VERSION ""

NS_ :

BS_:

BU_: ESC

VAL_TABLE_ RollingCounter_0x132 15 "Invalid";
VAL_TABLE_ ESC_HSA_Control_Status 1 "active" 0 "inactive";
VAL_TABLE_ ESC_HSA_Status_Fault 1 " HSA Defective" 0 "HSA Normale";
VAL_TABLE_ ESC_TcsDisableSts 3 "signal invalid" 2 "reservred" 1 "disabled" 0 "enabled";
VAL_TABLE_ ESC_TcsCtrlActv 1 "active" 0 "inactive";
VAL_TABLE_ ESC_TcsFlgFlt 1 "failure" 0 "no failure";
VAL_TABLE_ ESC_EscDisableSts 1 "disabled" 0 "enabled";
VAL_TABLE_ ESC_EscCtrlActv 1 "active" 0 "inactive";
VAL_TABLE_ ESC_EscFlgFlt 1 "failure" 0 "no failure";
VAL_TABLE_ ESC_HBAFlgFlt 1 "failure" 0 "no failure";
VAL_TABLE_ ESC_HbaCtrlActv 1 "active" 0 "inactive";
VAL_TABLE_ ESC_SlopeGradeAngle 255 "Invalid";
VAL_TABLE_ ESC_MasterCylinderPressure 4095 "Invalid";
VAL_TABLE_ RollingCounter_0x142 15 "Invalid";
VAL_TABLE_ AbsDiagSessionLampReq_Reserved 1 "lamp on" 0 "lamp off";
VAL_TABLE_ ABS_AbsCtrlActv 1 "active" 0 "inactive";
VAL_TABLE_ ABS_EbdFlgFlt 1 "failure" 0 "no failure";
VAL_TABLE_ ABS_AbsFlgFlt 1 "failure" 0 "no failure";
VAL_TABLE_ ABS_ESS_Active 1 "active" 0 "inactive";
VAL_TABLE_ ABS_LowBrakeFluid 1 "failure" 0 "no failure";
VAL_TABLE_ RollingCounter_0x332 15 "Invalid";
VAL_TABLE_ ABS_LFWhlSpdRaw 32767 "Invalid";
VAL_TABLE_ ABS_LFWhlSpdRawValid 1 "Valid" 0 "Invalid";
VAL_TABLE_ ABS_RFWhlSpdRaw 32767 "Invalid";
VAL_TABLE_ ABS_RFWhlSpdRawValid 1 "Valid" 0 "Invalid";
VAL_TABLE_ RollingCounter_0x342 15 "Invalid";
VAL_TABLE_ ABS_LRWhlSpdRaw 32767 "Invalid";
VAL_TABLE_ ABS_LRWhlSpdRawValid 1 "Valid" 0 "Invalid";
VAL_TABLE_ ABS_RRWhlSpdRaw 32767 "Invalid";
VAL_TABLE_ ABS_RRWhlSpdRawValid 1 "Valid" 0 "Invalid";
VAL_TABLE_ ABS_VehSpd 32767 "Invalid";
VAL_TABLE_ ABS_VehSpdValid 1 "Valid" 0 "Invalid";
VAL_TABLE_ ABS_WssLFPulseCounter 32767 "Invalid";
VAL_TABLE_ ABS_WssLFPulseCounterValid 1 "Valid" 0 "Invalid";
VAL_TABLE_ ABS_WssRFPulseCounter 32767 "Invalid";
VAL_TABLE_ ABS_WssRFPulseCounterValid 1 "Valid" 0 "Invalid";
VAL_TABLE_ ABS_WssLRPulseCounter 32767 "Invalid";
VAL_TABLE_ ABS_WssLRPulseCounterValid 1 "Valid" 0 "Invalid";
VAL_TABLE_ ABS_WssRRPulseCounter 32767 "Invalid";
VAL_TABLE_ ABS_WssRRPulseCounterValid 1 "Valid" 0 "Invalid";
VAL_TABLE_ RollingCounter_0x3E2 15 "Invalid";
VAL_TABLE_ ESC_LateralACC 255 "Invalid";
VAL_TABLE_ ESC_LateralACC_Valid 1 "Valid" 0 "Invalid";
VAL_TABLE_ ESC_LongitudeACC 1023 "Invalid";
VAL_TABLE_ ESC_LongitudeACC_Valid 1 "Valid" 0 "Invalid";
VAL_TABLE_ ESC_VehDynYawRate 16383 "Invalid";
VAL_TABLE_ ESC_VehDynYawRate_Valid 1 "Valid" 0 "Invalid";
VAL_TABLE_ RollingCounter_0x3F2 15 "Invalid";
VAL_TABLE_ ESC_VehicleACC 1023 "Invalid";
VAL_TABLE_ ESC_VehicleACC_Valid 1 "Valid" 0 "Invalid";
VAL_TABLE_ RollingCounter_362 15 "Invalid";
VAL_TABLE_ ESC_RegenDragCtrlStatus 1 "active" 0 "inactive";
VAL_TABLE_ ESC_RegenBrakeCtrlStatus 1 "active" 0 "inactive";
VAL_TABLE_ ESC_TorqReqMode 3 "Reserved" 2 "Regen mode" 1 "TCS mode" 0 "Normal mode";
VAL_TABLE_ ESC_TorqRequestVal 65535 "Invalid";
VAL_TABLE_ ESC_FLTirePressAlarm 1 "Pressure warning" 0 "No warning";
VAL_TABLE_ ESC_FRTirePressAlarm 1 "Pressure warning" 0 "No warning";
VAL_TABLE_ ESC_RLTirePressAlarm 1 "Pressure warning" 0 "No warning";
VAL_TABLE_ ESC_RRTirePressAlarm 1 "Pressure warning" 0 "No warning";
VAL_TABLE_ ESC_iTPMS_Err 1 "Error" 0 "No error";
VAL_TABLE_ ESC_iTPMS_WarnLampAct 1 "Active" 0 "Inactive";
VAL_TABLE_ ESC_iTPMSResetProhibit 3 "prohibit 3 (System error)" 2 "prohibit 2 (Vehicle speed >0 km/h)" 1 "prohibit 1 (Tire statue is changing)" 0 "Not prohibit";
VAL_TABLE_ ESC_iTPMSResetSts 4 "Reset fail" 3 "Reset finish" 2 "Reset ongoing" 1 "Reset start" 0 "Idle";
VAL_TABLE_ Rolling_counter_0x17E 15 "Invalid";
VAL_TABLE_ SAS_SteerWheelAngle 65535 "Invalid";
VAL_TABLE_ SAS_SteeringAngleValid 1 "Valid" 0 "Invalid";
VAL_TABLE_ SAS_SASStsSnsr 1 "sensor value valid" 0 "sensor value Invalid";
VAL_TABLE_ SAS_SteerWhlRotSpd 16383 "Invalid";
VAL_TABLE_ SAS_SteerWhlRotSpdStatus 1 "Valid" 0 "Invalid";
VAL_TABLE_ SAS_Calibrated 1 "Calibrated" 0 "Not Calibrated";
VAL_TABLE_ SAS_SASFailure 1 "No Failure" 0 "Failure";
VAL_TABLE_ RollingCounter_0x269 15 "Invalid";
VAL_TABLE_ VCU_VehicleHVStatus 3 "Reserved" 2 "ReadyToDrive" 1 "HV On" 0 "Not ready";
VAL_TABLE_ VCU_ActualGear 7 "Fault" 6 "Reserved" 5 "Reserved" 4 "Reserved" 3 "D" 2 "N" 1 "R" 0 "P reserved";
VAL_TABLE_ VCU_ActualGearValid 1 "Invalid" 0 "Valid";
VAL_TABLE_ VCU_AccPedalPosition 255 "Invalid";
VAL_TABLE_ VCU_AccPedalPositionValid 1 "Invalid" 0 "Valid";
VAL_TABLE_ VCU_TqReductionRqstResponse 1 "active" 0 "inactive";
VAL_TABLE_ VCU_BrakePedalSts 3 "Invalid" 2 "Reserved" 1 "pressed" 0 "Not pressed";
VAL_TABLE_ Rolling_Counter_0x20C 15 "Invalid";
VAL_TABLE_ IPC_ODO 1048575 "Invalid";
VAL_TABLE_ IPC_TripA 65535 "Invalid";
VAL_TABLE_ IPC_AverageSpeedTripA 4095 "Invalid";
VAL_TABLE_ IPC_AverageConsumptionTripA 1023 "Invalid";
VAL_TABLE_ IPC_ParkBrakeSts 3 "Invalid" 2 "Reserved" 1 "Applied" 0 "Released";
VAL_TABLE_ IPC_VehSpd 32767 "Invalid";
VAL_TABLE_ IPC_TireLearningReq_reserved 3 "Reserved" 2 "Reserved" 1 "Requset" 0 "No requset";
VAL_TABLE_ IPC_TireResetReq 3 "Reserved" 2 "Reserved" 1 "Requset to reset" 0 "No requset";
VAL_TABLE_ IPC_Sec 63 "Invalid";
VAL_TABLE_ IPC_Min 63 "Invalid";
VAL_TABLE_ IPC_Hour 31 "Invalid";
VAL_TABLE_ IPC_Day 31 "Invalid";
VAL_TABLE_ IPC_Month 15 "Invalid";
VAL_TABLE_ IPC_Year 255 "Invalid";
VAL_TABLE_ IPC_SelfCheckStatus 1 "self-check finish" 0 "self-checking";
VAL_TABLE_ Rolling_Counter_0x403 15 "Invalid";
VAL_TABLE_ MHU_SET_TCS_OnOff 0 "OFF (keep sending for 2 seconds)" 1 "ON (keep sending for 2 seconds)" 2 "No action" 3 "Invalid";
VAL_TABLE_ MHU_SET_DrivingModeSwitch 3 "sport mode (should be hold during 1 second)" 2 "normal mode (should be hold during 1 second)" 1 "eco mode (should be hold during 1 second)" 0 "no change request";
VAL_TABLE_ MHU_SET_RegenLevel 3 "No action" 2 "High" 1 "Low" 0 "none";
VAL_TABLE_ MHU_VCU_CreepDisable_stt 0 "No request" 1 "Creep Disable request" 2 "Reserved" 3 "Invalid";
VAL_TABLE_ MHU_HVACTurnON 0 "No request" 1 "ON" 2 "Reserved" 3 "Invalid";
VAL_TABLE_ MHU_ChargeScheduleSet 0 "Disabled" 1 "Enabled" 2 "No Action" 3 "Reserved";
VAL_TABLE_ MHU_ChargingRequest 0 "Reserved" 1 "Request scheduled start charging" 2 "Request stop" 3 "No effect";
VAL_TABLE_ MHU_ValetMode_Activation 0 "Inactive" 1 "Active" 254 "Reserved" 255 "Invalid";
VAL_TABLE_ BCM_STAT_DoorAjarDriver 3 "Signal invalid" 2 "Reserved" 1 "Opened" 0 "Closed";
VAL_TABLE_ BCM_PosLmpSts 0 "OFF" 1 "ON" 2 "Fault (Reserved)" 3 "Signal Invalid";
VAL_TABLE_ Rolling_Counter_0x10a 15 "Invalid";
VAL_TABLE_ BCM_LVTop_up 1 "start Top up" 0 "stop Top up";
VAL_TABLE_ Rolling_Counter_0x112 15 "Invalid";
VAL_TABLE_ STAT_Terminal 7 "Signal invalid" 6 "Reserved" 5 "Reserved" 4 "SW update OTA (Not used in VFe34)" 3 "Engine start (eMotor running)" 2 "ON (Driver Present)" 1 "ACC (Park)" 0 "OFF(Comfort Enable)";
VAL_TABLE_ STAT_CL30s_L_Reserved 3 "Signal invalid" 2 "Failure" 1 "ON" 0 "OFF";
VAL_TABLE_ Rolling_Counter_0x1F8 15 "Invalid";
VAL_TABLE_ EDS_output_trq_FR 65535 "Invalid";
VAL_TABLE_ EDS_output_trqValid_FR 1 "valid" 0 "invalid";
VAL_TABLE_ EDS_Spd_FR 65535 "Invalid";
VAL_TABLE_ EDS_SpdValid_FR 1 "valid" 0 "invalid";
VAL_TABLE_ EDS_MotorDriveSts_FR 3 "Invaild" 2 "regen control" 1 "Drive control" 0 "Zero control";
VAL_TABLE_ EDS_Work_STS_FR 15 "invaild" 14 "power off" 13 "Failure" 12 "after run" 11 "shut down" 5 "HVReady" 4 "normal" 3 "precharge" 2 "standby" 1 "init" 0 "default";
VAL_TABLE_ EDS_powoff_req_FR 1 "(Request high voltage power down)" 0 "(No request)";
VAL_TABLE_ VCU_DriveCoolWaterPumpSts 5 "Reserved" 4 "Other error" 3 "Overtemperature" 2 "Locked-rotor" 1 "Idle" 0 "Normal";
VAL_TABLE_ VCU_DriveCoolWaterDuty 127 "Invalid";
VAL_TABLE_ VCU_BatteryWaterPumpSts_reserved 5 "Reserved" 4 "Other error" 3 "Overtemperature" 2 "Locked-rotor" 1 "Idle" 0 "Normal";
VAL_TABLE_ VCU_BatteryWaterPumpDuty_reserved 127 "Invalid";
VAL_TABLE_ VCU_DriveMode 7 "Invalid" 6 "Reserved" 5 "Reserved" 4 "Reserved" 3 "Reserved" 2 "Sport mode" 1 "ECO mode" 0 "Normal mode";
VAL_TABLE_ VCU_ActualGear 7 "Fault" 6 "Reserved" 5 "Reserved" 4 "Reserved" 3 "D" 2 "N" 1 "R" 0 "P reserved";
VAL_TABLE_ VCU_ACTGearValid 1 "nvalid" 0 "Valid";
VAL_TABLE_ VCU_AccPedal1OutRange 1 "Error" 0 "Normal";
VAL_TABLE_ VCU_AccPedal2OutRange 1 "Error" 0 "Normal";
VAL_TABLE_ VCU_BrkPedal1OutRange 1 "Error" 0 "Normal";
VAL_TABLE_ VCU_BrkPedal2OutRange 1 "Error" 0 "Normal";
VAL_TABLE_ VCU_BrkPedalPct 255 "Invalid";
VAL_TABLE_ VCU_AccPedalPosition 255 "Invalid";
VAL_TABLE_ VCU_AccPedalPositionValid 1 "Invalid" 0 "Valid";
VAL_TABLE_ VCU_SocDisplay_EST 127 "Invalid";
VAL_TABLE_ VCU_PowerLimit 1 "Limit" 0 "No Limit";
VAL_TABLE_ VCU_CruiseCtrlSts 3 "takeover mode" 2 "Pre cruise(lamp flash)" 1 "Cruise on(lamp on)" 0 "Cruise off(lamp off)";
VAL_TABLE_ VCU_LowSOC_ERR 1 "Error" 0 "No Error";
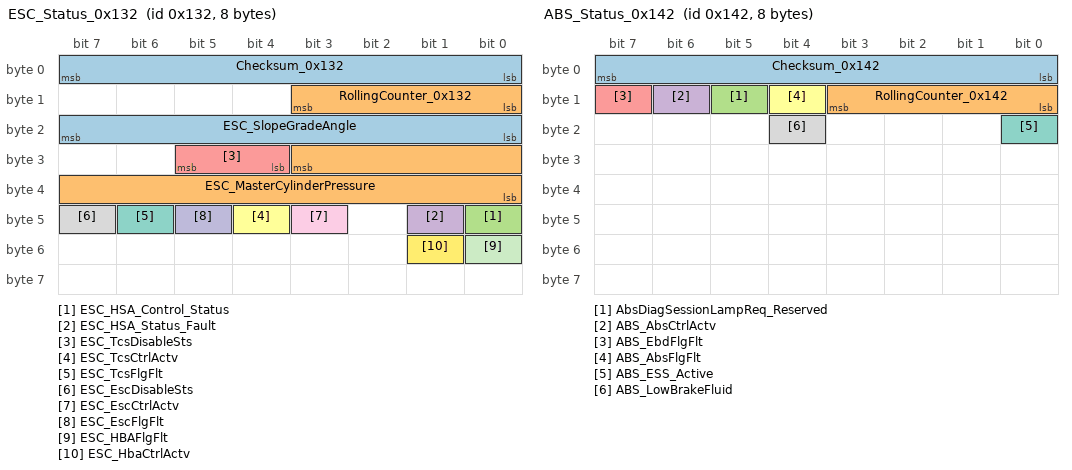
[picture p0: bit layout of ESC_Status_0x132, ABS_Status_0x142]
BO_ 306 ESC_Status_0x132: 8 ESC
 SG_ Checksum_0x132 : 7|8@0+ (1,0) [0|255] "" Vector__XXX
 SG_ RollingCounter_0x132 : 11|4@0+ (1,0) [0|15] "" Vector__XXX
 SG_ ESC_HSA_Control_Status : 40|1@0+ (1,0) [0|1] "" Vector__XXX
 SG_ ESC_HSA_Status_Fault : 41|1@0+ (1,0) [0|1] "" Vector__XXX
 SG_ ESC_TcsDisableSts : 29|2@0+ (1,0) [0|3] "" Vector__XXX
 SG_ ESC_TcsCtrlActv : 44|1@0+ (1,0) [0|1] "" Vector__XXX
 SG_ ESC_TcsFlgFlt : 46|1@0+ (1,0) [0|1] "" Vector__XXX
 SG_ ESC_EscDisableSts : 47|1@0+ (1,0) [0|1] "" Vector__XXX
 SG_ ESC_EscCtrlActv : 43|1@0+ (1,0) [0|1] "" Vector__XXX
 SG_ ESC_EscFlgFlt : 45|1@0+ (1,0) [0|1] "" Vector__XXX
 SG_ ESC_HBAFlgFlt : 48|1@0+ (1,0) [0|1] "" Vector__XXX
 SG_ ESC_HbaCtrlActv : 49|1@0+ (1,0) [0|1] "" Vector__XXX
 SG_ ESC_SlopeGradeAngle : 23|8@0+ (0.35433,-45) [-45|45] "deg" Vector__XXX
 SG_ ESC_MasterCylinderPressure : 27|12@0+ (0.1,-100) [-100|309.4] "bar" Vector__XXX
BO_ 322 ABS_Status_0x142: 8 ESC
 SG_ Checksum_0x142 : 7|8@0+ (1,0) [0|255] "" Vector__XXX
 SG_ RollingCounter_0x142 : 11|4@0+ (1,0) [0|15] "" Vector__XXX
 SG_ AbsDiagSessionLampReq_Reserved : 13|1@0+ (1,0) [0|1] "" Vector__XXX
 SG_ ABS_AbsCtrlActv : 14|1@0+ (1,0) [0|1] "" Vector__XXX
 SG_ ABS_EbdFlgFlt : 15|1@0+ (1,0) [0|1] "" Vector__XXX
 SG_ ABS_AbsFlgFlt : 12|1@0+ (1,0) [0|1] "" Vector__XXX
 SG_ ABS_ESS_Active : 16|1@0+ (1,0) [0|1] "" Vector__XXX
 SG_ ABS_LowBrakeFluid : 20|1@0+ (1,0) [0|1] "" Vector__XXX
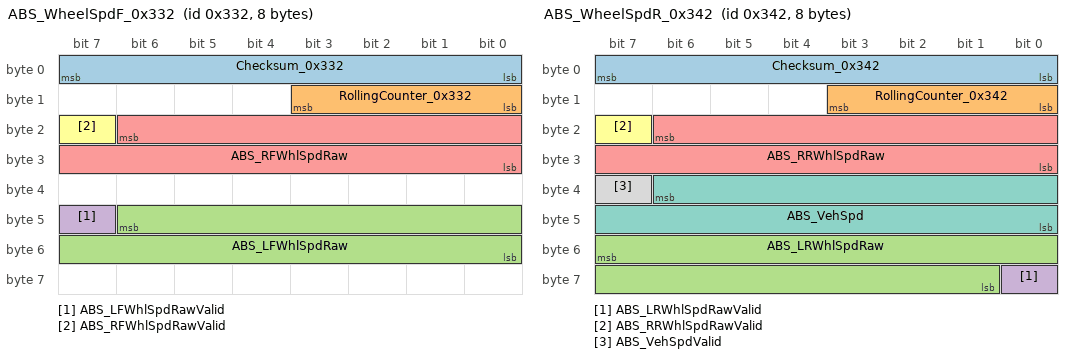
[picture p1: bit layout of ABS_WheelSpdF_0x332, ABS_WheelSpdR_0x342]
BO_ 818 ABS_WheelSpdF_0x332: 8 ESC
 SG_ Checksum_0x332 : 7|8@0+ (1,0) [0|255] "" Vector__XXX
 SG_ RollingCounter_0x332 : 11|4@0+ (1,0) [0|15] "" Vector__XXX
 SG_ ABS_LFWhlSpdRaw : 46|15@0+ (0.01,0) [0|327.66] "kph" Vector__XXX
 SG_ ABS_LFWhlSpdRawValid : 47|1@0+ (1,0) [0|1] "" Vector__XXX
 SG_ ABS_RFWhlSpdRaw : 22|15@0+ (0.01,0) [0|327.66] "kph" Vector__XXX
 SG_ ABS_RFWhlSpdRawValid : 23|1@0+ (1,0) [0|1] "" Vector__XXX
BO_ 834 ABS_WheelSpdR_0x342: 8 ESC
 SG_ Checksum_0x342 : 7|8@0+ (1,0) [0|255] "" Vector__XXX
 SG_ RollingCounter_0x342 : 11|4@0+ (1,0) [0|15] "" Vector__XXX
 SG_ ABS_LRWhlSpdRaw : 55|15@0+ (0.01,0) [0|327.66] "kph" Vector__XXX
 SG_ ABS_LRWhlSpdRawValid : 56|1@0+ (1,0) [0|1] "" Vector__XXX
 SG_ ABS_RRWhlSpdRaw : 22|15@0+ (0.01,0) [0|327.66] "kph" Vector__XXX
 SG_ ABS_RRWhlSpdRawValid : 23|1@0+ (1,0) [0|1] "" Vector__XXX
 SG_ ABS_VehSpd : 38|15@0+ (0.01,0) [0|327.66] "kph" Vector__XXX
 SG_ ABS_VehSpdValid : 39|1@0+ (1,0) [0|1] "" Vector__XXX
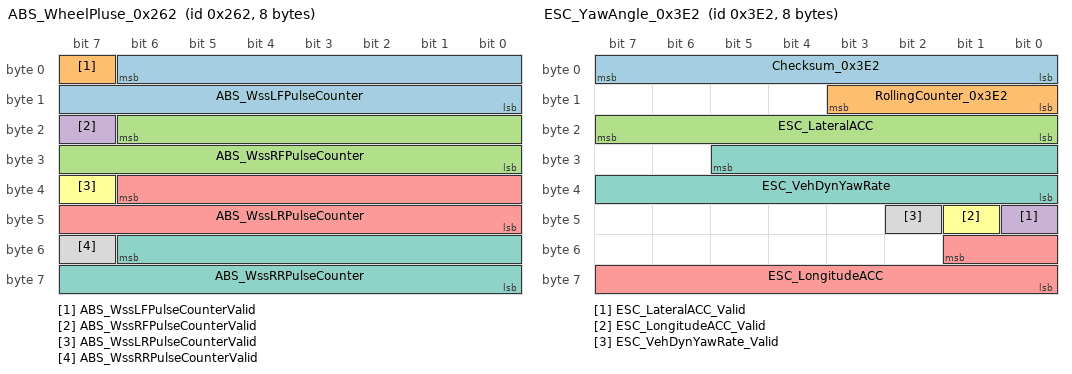
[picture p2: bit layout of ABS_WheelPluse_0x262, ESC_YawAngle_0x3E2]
BO_ 610 ABS_WheelPluse_0x262: 8 ESC
 SG_ ABS_WssLFPulseCounter : 6|15@0+ (1,0) [0|32766] "pluse" Vector__XXX
 SG_ ABS_WssLFPulseCounterValid : 7|1@0+ (1,0) [0|1] "" Vector__XXX
 SG_ ABS_WssRFPulseCounter : 22|15@0+ (1,0) [0|32766] "pluse" Vector__XXX
 SG_ ABS_WssRFPulseCounterValid : 23|1@0+ (1,0) [0|1] "" Vector__XXX
 SG_ ABS_WssLRPulseCounter : 38|15@0+ (1,0) [0|32766] "pluse" Vector__XXX
 SG_ ABS_WssLRPulseCounterValid : 39|1@0+ (1,0) [0|1] "" Vector__XXX
 SG_ ABS_WssRRPulseCounter : 54|15@0+ (1,0) [0|32766] "pluse" Vector__XXX
 SG_ ABS_WssRRPulseCounterValid : 55|1@0+ (1,0) [0|1] "" Vector__XXX
BO_ 994 ESC_YawAngle_0x3E2: 8 ESC
 SG_ Checksum_0x3E2 : 7|8@0+ (1,0) [0|255] "" Vector__XXX
 SG_ RollingCounter_0x3E2 : 11|4@0+ (1,0) [0|15] "" Vector__XXX
 SG_ ESC_LateralACC : 23|8@0+ (0.01587,-2.0193) [-2.0193|2.0193] "g" Vector__XXX
 SG_ ESC_LateralACC_Valid : 40|1@0+ (1,0) [0|1] "" Vector__XXX
 SG_ ESC_LongitudeACC : 49|10@0+ (0.00392,-1.9929) [-1.9929|1.9929] "g" Vector__XXX
 SG_ ESC_LongitudeACC_Valid : 41|1@0+ (1,0) [0|1] "" Vector__XXX
 SG_ ESC_VehDynYawRate : 29|14@0+ (0.03125,-256) [-256|255.96875] "deg/s" Vector__XXX
 SG_ ESC_VehDynYawRate_Valid : 42|1@0+ (1,0) [0|1] "" Vector__XXX
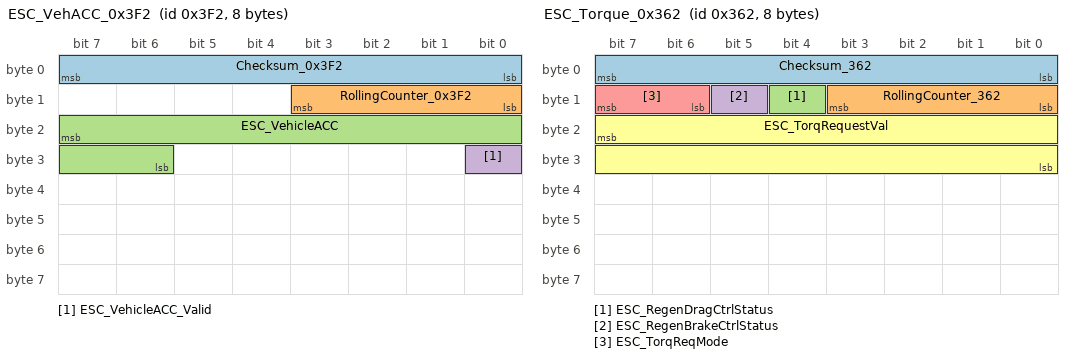
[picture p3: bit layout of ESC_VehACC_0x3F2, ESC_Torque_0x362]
BO_ 1010 ESC_VehACC_0x3F2: 8 ESC
 SG_ Checksum_0x3F2 : 7|8@0+ (1,0) [0|255] "" Vector__XXX
 SG_ RollingCounter_0x3F2 : 11|4@0+ (1,0) [0|15] "" Vector__XXX
 SG_ ESC_VehicleACC : 23|10@0+ (0.00392,-1.9929) [-1.9929|1.9929] "g" Vector__XXX
 SG_ ESC_VehicleACC_Valid : 24|1@0+ (1,0) [0|1] "" Vector__XXX
BO_ 866 ESC_Torque_0x362: 8 ESC
 SG_ Checksum_362 : 7|8@0+ (1,0) [0|255] "" Vector__XXX
 SG_ RollingCounter_362 : 11|4@0+ (1,0) [0|15] "" Vector__XXX
 SG_ ESC_RegenDragCtrlStatus : 12|1@0+ (1,0) [0|1] "" Vector__XXX
 SG_ ESC_RegenBrakeCtrlStatus : 13|1@0+ (1,0) [0|1] "" Vector__XXX
 SG_ ESC_TorqReqMode : 15|2@0+ (1,0) [0|3] "" Vector__XXX
 SG_ ESC_TorqRequestVal : 23|16@0+ (0.05,-1000) [-1000|1000] "Nm" Vector__XXX
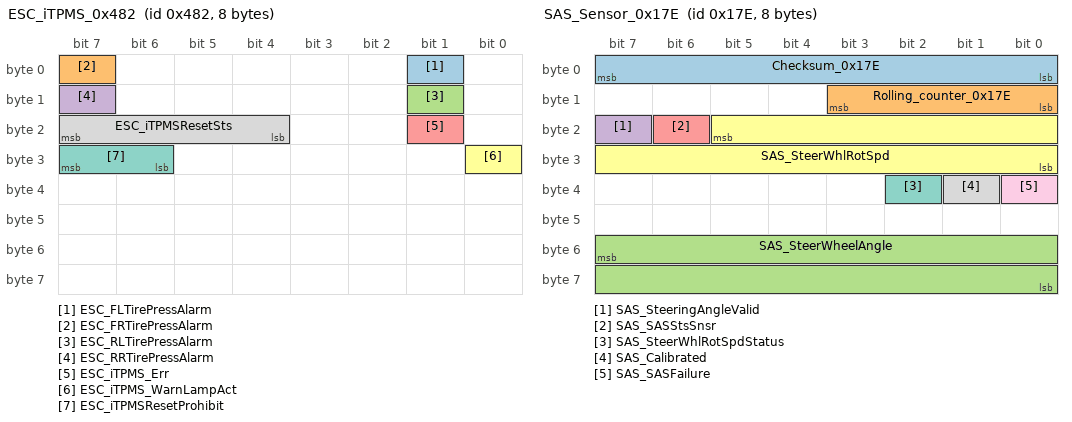
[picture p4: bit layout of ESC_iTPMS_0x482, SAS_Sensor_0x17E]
BO_ 1154 ESC_iTPMS_0x482: 8 ESC
 SG_ ESC_FLTirePressAlarm : 1|1@0+ (1,0) [0|1] "" Vector__XXX
 SG_ ESC_FRTirePressAlarm : 7|1@0+ (1,0) [0|1] "" Vector__XXX
 SG_ ESC_RLTirePressAlarm : 9|1@0+ (1,0) [0|1] "" Vector__XXX
 SG_ ESC_RRTirePressAlarm : 15|1@0+ (1,0) [0|1] "" Vector__XXX
 SG_ ESC_iTPMS_Err : 17|1@0+ (1,0) [0|1] "" Vector__XXX
 SG_ ESC_iTPMS_WarnLampAct : 24|1@0+ (1,0) [0|1] "" Vector__XXX
 SG_ ESC_iTPMSResetProhibit : 31|2@0+ (1,0) [0|3] "" Vector__XXX
 SG_ ESC_iTPMSResetSts : 23|4@0+ (1,0) [0|15] "" Vector__XXX
BO_ 382 SAS_Sensor_0x17E: 8 Vector__XXX
 SG_ Checksum_0x17E : 7|8@0+ (1,0) [0|255] "" ESC
 SG_ Rolling_counter_0x17E : 11|4@0+ (1,0) [0|15] "" ESC
 SG_ SAS_SteerWheelAngle : 55|16@0+ (0.0238,-780) [-780|779.7] "deg" ESC
 SG_ SAS_SteeringAngleValid : 23|1@0+ (1,0) [0|1] "" ESC
 SG_ SAS_SASStsSnsr : 22|1@0+ (1,0) [0|1] "" ESC
 SG_ SAS_SteerWhlRotSpd : 21|14@0+ (0.125,-1024) [-1024|1023.75] "degs" ESC
 SG_ SAS_SteerWhlRotSpdStatus : 34|1@0+ (1,0) [0|1] "" ESC
 SG_ SAS_Calibrated : 33|1@0+ (1,0) [0|1] "" ESC
 SG_ SAS_SASFailure : 32|1@0+ (1,0) [0|1] "" ESC
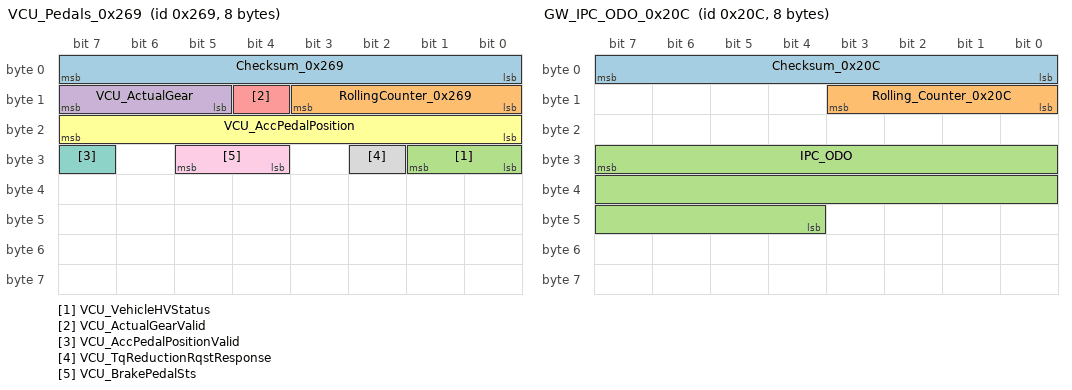
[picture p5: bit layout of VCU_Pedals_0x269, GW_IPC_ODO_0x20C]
BO_ 617 VCU_Pedals_0x269: 8 Vector__XXX
 SG_ Checksum_0x269 : 7|8@0+ (1,0) [0|255] "" ESC
 SG_ RollingCounter_0x269 : 11|4@0+ (1,0) [0|15] "" ESC
 SG_ VCU_VehicleHVStatus : 25|2@0+ (1,0) [0|3] "" ESC
 SG_ VCU_ActualGear : 15|3@0+ (1,0) [0|7] "" ESC
 SG_ VCU_ActualGearValid : 12|1@0+ (1,0) [0|1] "" ESC
 SG_ VCU_AccPedalPosition : 23|8@0+ (0.4,0) [0|100] "%" ESC
 SG_ VCU_AccPedalPositionValid : 31|1@0+ (1,0) [0|1] "" ESC
 SG_ VCU_TqReductionRqstResponse : 26|1@0+ (1,0) [0|1] "" Vector__XXX
 SG_ VCU_BrakePedalSts : 29|2@0+ (1,0) [0|3] "" ESC
BO_ 524 GW_IPC_ODO_0x20C: 8 Vector__XXX
 SG_ Checksum_0x20C : 7|8@0+ (1,0) [0|255] "" ESC
 SG_ Rolling_Counter_0x20C : 11|4@0+ (1,0) [0|15] "" ESC
 SG_ IPC_ODO : 31|20@0+ (1,0) [0|999999] "km" ESC
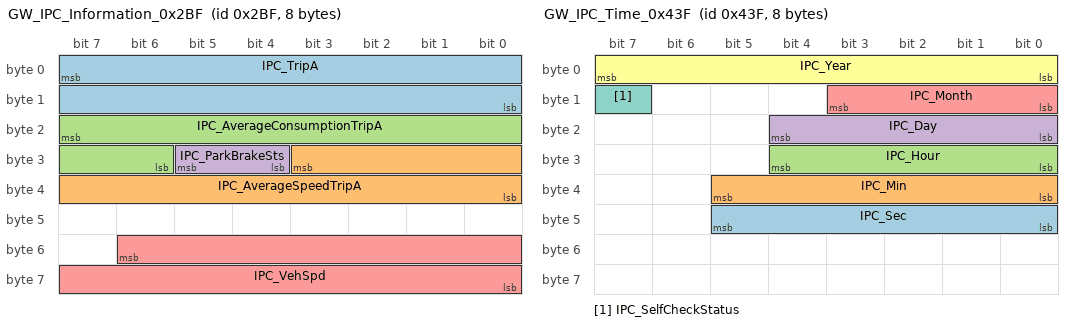
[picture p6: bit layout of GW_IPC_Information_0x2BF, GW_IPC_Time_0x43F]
BO_ 703 GW_IPC_Information_0x2BF: 8 Vector__XXX
 SG_ IPC_TripA : 7|16@0+ (0.1,0) [0|999.9] "km" Vector__XXX
 SG_ IPC_AverageSpeedTripA : 27|12@0+ (0.0625,0) [0|250] "km/h" Vector__XXX
 SG_ IPC_AverageConsumptionTripA : 23|10@0+ (0.1,0) [0|100] "kwh/100km" Vector__XXX
 SG_ IPC_ParkBrakeSts : 29|2@0+ (1,0) [0|3] "" ESC
 SG_ IPC_VehSpd : 54|15@0+ (0.01,0) [0|327.66] "kph" Vector__XXX
BO_ 735 GW_IPC_TPMSReq_0x2DF: 8 Vector__XXX
 SG_ IPC_TireLearningReq_reserved : 1|2@0+ (1,0) [0|3] "" Vector__XXX
 SG_ IPC_TireResetReq : 7|2@0+ (1,0) [0|3] "" ESC
BO_ 1087 GW_IPC_Time_0x43F: 8 Vector__XXX
 SG_ IPC_Sec : 45|6@0+ (1,0) [0|59] "second" ESC
 SG_ IPC_Min : 37|6@0+ (1,0) [0|59] "min" ESC
 SG_ IPC_Hour : 28|5@0+ (1,0) [0|23] "hour" ESC
 SG_ IPC_Day : 20|5@0+ (1,0) [1|31] "" ESC
 SG_ IPC_Month : 11|4@0+ (1,0) [1|12] "" ESC
 SG_ IPC_Year : 7|8@0+ (1,2000) [2000|2255] "" ESC
 SG_ IPC_SelfCheckStatus : 15|1@0+ (1,0) [0|1] "" ESC
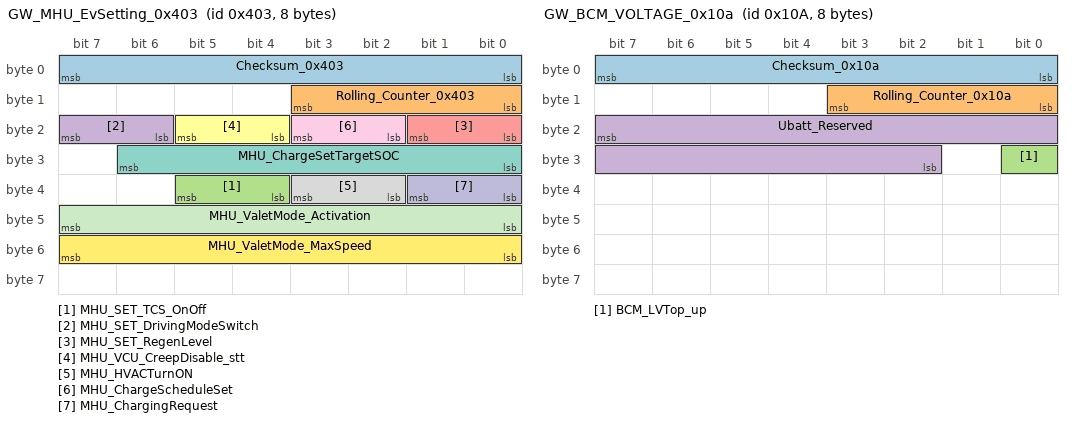
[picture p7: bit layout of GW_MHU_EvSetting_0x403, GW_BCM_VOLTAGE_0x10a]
BO_ 1027 GW_MHU_EvSetting_0x403: 8 Vector__XXX
 SG_ Checksum_0x403 : 7|8@0+ (1,0) [0|255] "" ESC
 SG_ Rolling_Counter_0x403 : 11|4@0+ (1,0) [0|15] "" ESC
 SG_ MHU_SET_TCS_OnOff : 37|2@0+ (1,0) [0|3] "" ESC
 SG_ MHU_SET_DrivingModeSwitch : 23|2@0+ (1,0) [0|3] "" Vector__XXX
 SG_ MHU_SET_RegenLevel : 17|2@0+ (1,0) [0|3] "" Vector__XXX
 SG_ MHU_VCU_CreepDisable_stt : 21|2@0+ (1,0) [0|3] "" Vector__XXX
 SG_ MHU_ChargeSetTargetSOC : 30|7@0+ (1,0) [10|100] "Percentage" Vector__XXX
 SG_ MHU_HVACTurnON : 35|2@0+ (1,0) [0|3] "" Vector__XXX
 SG_ MHU_ChargeScheduleSet : 19|2@0+ (1,0) [0|3] "" Vector__XXX
 SG_ MHU_ChargingRequest : 33|2@0+ (1,0) [0|3] "" Vector__XXX
 SG_ MHU_ValetMode_Activation : 47|8@0+ (1,0) [0|254] "" Vector__XXX
 SG_ MHU_ValetMode_MaxSpeed : 55|8@0+ (1,0) [0|254] "kph" Vector__XXX
BO_ 848 GW_Body_Switch_0x350: 8 Vector__XXX
 SG_ BCM_STAT_DoorAjarDriver : 7|2@0+ (1,0) [0|3] "Bit" ESC
 SG_ BCM_PosLmpSts : 15|2@0+ (1,0) [0|3] "" Vector__XXX
BO_ 266 GW_BCM_VOLTAGE_0x10a: 8 Vector__XXX
 SG_ Checksum_0x10a : 7|8@0+ (1,0) [0|255] "" ESC
 SG_ Rolling_Counter_0x10a : 11|4@0+ (1,0) [0|15] "" ESC
 SG_ BCM_LVTop_up : 24|1@0+ (1,0) [0|1] "" Vector__XXX
 SG_ Ubatt_Reserved : 23|14@0+ (0.001,3) [3|18] "V" ESC
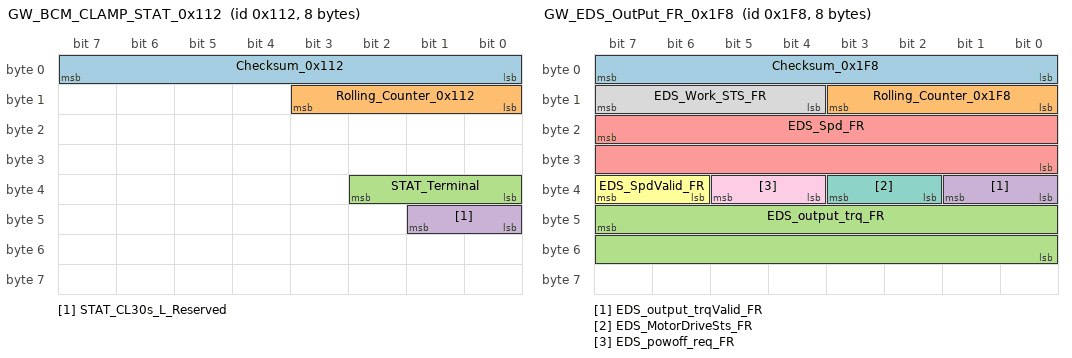
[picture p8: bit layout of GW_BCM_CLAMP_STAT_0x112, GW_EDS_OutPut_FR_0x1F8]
BO_ 274 GW_BCM_CLAMP_STAT_0x112: 8 Vector__XXX
 SG_ Checksum_0x112 : 7|8@0+ (1,0) [0|255] "" ESC
 SG_ Rolling_Counter_0x112 : 11|4@0+ (1,0) [0|15] "" ESC
 SG_ STAT_Terminal : 34|3@0+ (1,0) [0|7] "Bit" ESC
 SG_ STAT_CL30s_L_Reserved : 41|2@0+ (1,0) [0|3] "Bit" Vector__XXX
BO_ 504 GW_EDS_OutPut_FR_0x1F8: 8 Vector__XXX
 SG_ Checksum_0x1F8 : 7|8@0+ (1,0) [0|255] "" ESC
 SG_ Rolling_Counter_0x1F8 : 11|4@0+ (1,0) [0|15] "" ESC
 SG_ EDS_output_trq_FR : 47|16@0+ (1,-2000) [-2000|2000] "Nm" ESC
 SG_ EDS_output_trqValid_FR : 33|2@0+ (1,0) [0|1] "" ESC
 SG_ EDS_Spd_FR : 23|16@0+ (1,-20000) [-20000|20000] "rpm" ESC
 SG_ EDS_SpdValid_FR : 39|2@0+ (1,0) [0|1] "" ESC
 SG_ EDS_MotorDriveSts_FR : 35|2@0+ (1,0) [0|3] "" ESC
 SG_ EDS_Work_STS_FR : 15|4@0+ (1,0) [0|15] "" ESC
 SG_ EDS_powoff_req_FR : 37|2@0+ (1,0) [0|1] "" ESC
BO_ 889 GW_VCU_Sts2_0x379: 8 Vector__XXX
 SG_ VCU_DriveCoolWaterPumpSts : 2|3@0+ (1,0) [0|5] "" Vector__XXX
 SG_ VCU_DriveCoolWaterDuty : 14|7@0+ (1,0) [0|100] "%" Vector__XXX
 SG_ VCU_BatteryWaterPumpSts_reserved : 30|3@0+ (1,0) [0|7] "" Vector__XXX
 SG_ VCU_BatteryWaterPumpDuty_reserved : 22|7@0+ (1,0) [0|100] "%" Vector__XXX
 SG_ VCU_DriveMode : 5|3@0+ (1,0) [0|7] "" Vector__XXX
 SG_ VCU_ActualGear : 26|3@0+ (1,0) [0|7] "" Vector__XXX
 SG_ VCU_ACTGearValid : 27|1@0+ (1,0) [0|1] "" Vector__XXX
 SG_ VCU_AccPedal1OutRange : 31|1@0+ (1,0) [0|1] "" Vector__XXX
 SG_ VCU_AccPedal2OutRange : 33|1@0+ (1,0) [0|1] "" Vector__XXX
 SG_ VCU_BrkPedal1OutRange : 35|1@0+ (1,0) [0|1] "" Vector__XXX
 SG_ VCU_BrkPedal2OutRange : 37|1@0+ (1,0) [0|1] "" Vector__XXX
 SG_ VCU_BrkPedalPct : 47|8@0+ (0.4,0) [0|100] "%" Vector__XXX
 SG_ VCU_AccPedalPosition : 55|8@0+ (0.4,0) [0|100] "%" Vector__XXX
 SG_ VCU_AccPedalPositionValid : 63|1@0+ (1,0) [0|1] "" Vector__XXX
 SG_ VCU_SocDisplay_EST : 62|7@0+ (1,0) [0|100] "%" Vector__XXX
 SG_ VCU_PowerLimit : 15|1@0+ (1,0) [0|1] "" Vector__XXX
 SG_ VCU_CruiseCtrlSts : 39|2@0+ (1,0) [0|3] "" ESC
 SG_ VCU_LowSOC_ERR : 23|1@0+ (1,0) [0|1] "" Vector__XXX
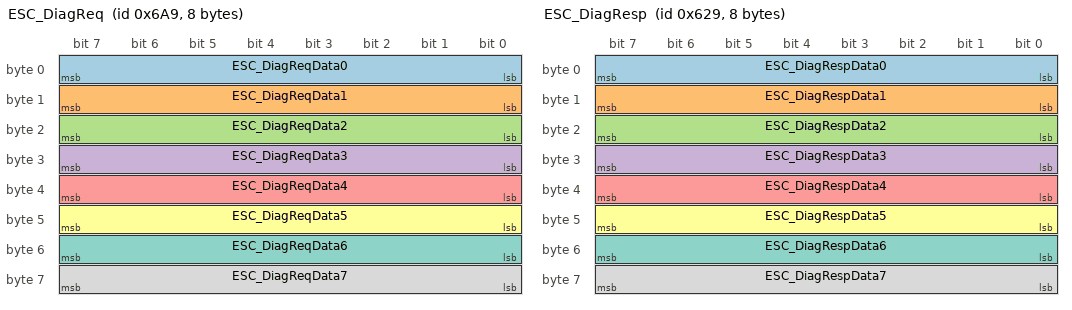
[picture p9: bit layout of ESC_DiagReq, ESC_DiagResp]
BO_ 1705 ESC_DiagReq: 8 Vector__XXX
 SG_ ESC_DiagReqData0 : 7|8@0+ (1,0) [0|255] "" ESC
 SG_ ESC_DiagReqData1 : 15|8@0+ (1,0) [0|255] "" ESC
 SG_ ESC_DiagReqData2 : 23|8@0+ (1,0) [0|255] "" ESC
 SG_ ESC_DiagReqData3 : 31|8@0+ (1,0) [0|255] "" ESC
 SG_ ESC_DiagReqData4 : 39|8@0+ (1,0) [0|255] "" ESC
 SG_ ESC_DiagReqData5 : 47|8@0+ (1,0) [0|255] "" ESC
 SG_ ESC_DiagReqData6 : 55|8@0+ (1,0) [0|255] "" ESC
 SG_ ESC_DiagReqData7 : 63|8@0+ (1,0) [0|255] "" ESC
BO_ 1577 ESC_DiagResp: 8 ESC
 SG_ ESC_DiagRespData0 : 7|8@0+ (1,0) [0|255] "" Vector__XXX
 SG_ ESC_DiagRespData1 : 15|8@0+ (1,0) [0|255] "" Vector__XXX
 SG_ ESC_DiagRespData2 : 23|8@0+ (1,0) [0|255] "" Vector__XXX
 SG_ ESC_DiagRespData3 : 31|8@0+ (1,0) [0|255] "" Vector__XXX
 SG_ ESC_DiagRespData4 : 39|8@0+ (1,0) [0|255] "" Vector__XXX
 SG_ ESC_DiagRespData5 : 47|8@0+ (1,0) [0|255] "" Vector__XXX
 SG_ ESC_DiagRespData6 : 55|8@0+ (1,0) [0|255] "" Vector__XXX
 SG_ ESC_DiagRespData7 : 63|8@0+ (1,0) [0|255] "" Vector__XXX
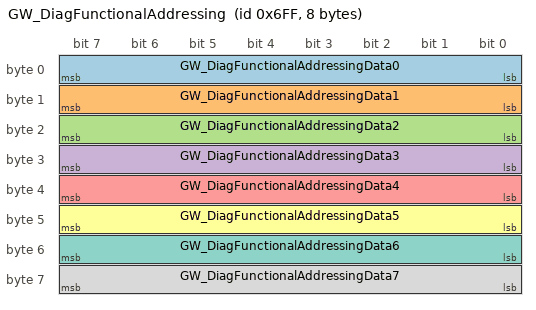
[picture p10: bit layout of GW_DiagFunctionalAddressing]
BO_ 1791 GW_DiagFunctionalAddressing: 8 Vector__XXX
 SG_ GW_DiagFunctionalAddressingData0 : 7|8@0+ (1,0) [0|255] "" ESC
 SG_ GW_DiagFunctionalAddressingData1 : 15|8@0+ (1,0) [0|255] "" ESC
 SG_ GW_DiagFunctionalAddressingData2 : 23|8@0+ (1,0) [0|255] "" ESC
 SG_ GW_DiagFunctionalAddressingData3 : 31|8@0+ (1,0) [0|255] "" ESC
 SG_ GW_DiagFunctionalAddressingData4 : 39|8@0+ (1,0) [0|255] "" ESC
 SG_ GW_DiagFunctionalAddressingData5 : 47|8@0+ (1,0) [0|255] "" ESC
 SG_ GW_DiagFunctionalAddressingData6 : 55|8@0+ (1,0) [0|255] "" ESC
 SG_ GW_DiagFunctionalAddressingData7 : 63|8@0+ (1,0) [0|255] "" ESC
CM_ SG_ 306 Checksum_0x132 "check sum";
CM_ SG_ 306 RollingCounter_0x132 "Rolling counter";
CM_ SG_ 306 ESC_HSA_Control_Status "Indicate HSA function is active or not";
CM_ SG_ 306 ESC_HSA_Status_Fault "Detect the HAS Fault status";
CM_ SG_ 306 ESC_TcsDisableSts "Indicate the TCS function can use or not";
CM_ SG_ 306 ESC_TcsCtrlActv "Indicate TCS  function is active or not";
CM_ SG_ 306 ESC_TcsFlgFlt "Detect the TCS function fault status";
CM_ SG_ 306 ESC_EscDisableSts "Indicate the ESC function can use or not";
CM_ SG_ 306 ESC_EscCtrlActv "Indicate ESC  function is active or not";
CM_ SG_ 306 ESC_EscFlgFlt "Detect the ESC function fault status";
CM_ SG_ 306 ESC_HBAFlgFlt "Detect the HBA(Hydraulic Brake Assist) function status";
CM_ SG_ 306 ESC_HbaCtrlActv "Indicate HBA(Hydraulic Brake Assist)   function is active or not";
CM_ SG_ 306 ESC_SlopeGradeAngle "Vehicle slope,Uphill is negative (head is higher than tail), downhill is positive (tail is higher than head)";
CM_ SG_ 306 ESC_MasterCylinderPressure "Master cylinder pressure";
CM_ SG_ 322 Checksum_0x142 "check sum";
CM_ SG_ 322 RollingCounter_0x142 "Rolling counter";
CM_ SG_ 322 AbsDiagSessionLampReq_Reserved "ABS or ESC is currently in safety system diagnostic  session,(DVT mode) need cluster to turn on ESC/TCS, EBD, ABS fault lamp";
CM_ SG_ 322 ABS_AbsCtrlActv "ABS status(Indiacte ABS  function is active or not.When ABS intervention starts,it sets as 1)";
CM_ SG_ 322 ABS_EbdFlgFlt "The EBD system fault, The EBD warning lamp should be open,The signal will be set as  whenEBD is disable due to fault";
CM_ SG_ 322 ABS_AbsFlgFlt "The ABS system fault, The ABS warning lamp should be open,The signal will be set as whenABS is disable due to fault";
CM_ SG_ 322 ABS_ESS_Active "Emergency Stop Signaling Active,when emergency stop, this signal will set true";
CM_ SG_ 322 ABS_LowBrakeFluid "Detect the brake fluid level";
CM_ SG_ 818 Checksum_0x332 "check sum";
CM_ SG_ 818 RollingCounter_0x332 "Rolling counter";
CM_ SG_ 818 ABS_LFWhlSpdRaw "Current Raw wheel speed information of front left wheel.";
CM_ SG_ 818 ABS_LFWhlSpdRawValid "Current Raw wheel speed information valid flag of front left wheel.";
CM_ SG_ 818 ABS_RFWhlSpdRaw "Current Raw wheel speed information of front right wheel.";
CM_ SG_ 818 ABS_RFWhlSpdRawValid "Current Raw wheel speed information valid flag of front right wheel.";
CM_ SG_ 834 Checksum_0x342 "Check sum";
CM_ SG_ 834 RollingCounter_0x342 "Rolling Counter";
CM_ SG_ 834 ABS_LRWhlSpdRaw "Current Raw wheel speed information of rear left wheel.";
CM_ SG_ 834 ABS_LRWhlSpdRawValid "Current Raw wheel speed information valid flag of rear left wheel.";
CM_ SG_ 834 ABS_RRWhlSpdRaw "Current Raw wheel speed information of rear right wheel.,";
CM_ SG_ 834 ABS_RRWhlSpdRawValid "Current Raw wheel speed information valid flag of rear right wheel";
CM_ SG_ 834 ABS_VehSpd "Current Longitudinal Vehicle Speed";
CM_ SG_ 834 ABS_VehSpdValid "Speed Valid Flag";
CM_ SG_ 610 ABS_WssLFPulseCounter "left front wheel pluse counter";
CM_ SG_ 610 ABS_WssLFPulseCounterValid "left front wheel pluse counter valid";
CM_ SG_ 610 ABS_WssRFPulseCounter "right front wheel pluse counter";
CM_ SG_ 610 ABS_WssRFPulseCounterValid "right front wheel pluse counter valid";
CM_ SG_ 610 ABS_WssLRPulseCounter "left rear wheel pluse counter";
CM_ SG_ 610 ABS_WssLRPulseCounterValid "left rear wheel pluse counter valid";
CM_ SG_ 610 ABS_WssRRPulseCounter "right rear wheel pluse counter";
CM_ SG_ 610 ABS_WssRRPulseCounterValid "right rear wheel pluse counter valid";
CM_ SG_ 994 Checksum_0x3E2 "check sum";
CM_ SG_ 994 RollingCounter_0x3E2 "Rolling counter";
CM_ SG_ 994 ESC_LateralACC "Indicate lateral acceleration";
CM_ SG_ 994 ESC_LateralACC_Valid "Valid flag of lateral acceleration";
CM_ SG_ 994 ESC_LongitudeACC "Indicate longitude acceleration";
CM_ SG_ 994 ESC_LongitudeACC_Valid "Valid flag of longitude acceleration";
CM_ SG_ 994 ESC_VehDynYawRate "Indicate the yaw rate";
CM_ SG_ 994 ESC_VehDynYawRate_Valid "Valid flag of yaw rate";
CM_ SG_ 1010 Checksum_0x3F2 "check sum";
CM_ SG_ 1010 RollingCounter_0x3F2 "Rolling counter";
CM_ SG_ 1010 ESC_VehicleACC "vehicle acceleration";
CM_ SG_ 1010 ESC_VehicleACC_Valid "Valid flag of vehicle acceleration";
CM_ SG_ 866 Checksum_362 "check sum";
CM_ SG_ 866 RollingCounter_362 "Rolling counter";
CM_ SG_ 866 ESC_RegenDragCtrlStatus "Indicate RDC  function is active or not";
CM_ SG_ 866 ESC_RegenBrakeCtrlStatus "Indicate RBC  function is active or not";
CM_ SG_ 866 ESC_TorqReqMode "Indicate the torque request mode";
CM_ SG_ 866 ESC_TorqRequestVal "Regen torque request and TCS torque request(in motor torque domain)";
CM_ SG_ 1154 ESC_FLTirePressAlarm "Front left tire pressure alarm signal";
CM_ SG_ 1154 ESC_FRTirePressAlarm "Front right tire pressure alarm signal";
CM_ SG_ 1154 ESC_RLTirePressAlarm "Rear left tire pressure alarm signal";
CM_ SG_ 1154 ESC_RRTirePressAlarm "Rear right tire pressure alarm signal";
CM_ SG_ 1154 ESC_iTPMS_Err "Failure of tire pressure monitoring system";
CM_ SG_ 1154 ESC_iTPMS_WarnLampAct "The status of TPMS warning lamp";
CM_ SG_ 1154 ESC_iTPMSResetProhibit "Indicate whether calibration is allowed";
CM_ SG_ 1154 ESC_iTPMSResetSts "Tire pressure system reset status";
CM_ SG_ 382 Checksum_0x17E "Check sum";
CM_ SG_ 382 Rolling_counter_0x17E "Rolling Counter";
CM_ SG_ 382 SAS_SteerWheelAngle "The current angle of the steering wheel(Positive, to left; Negative, to right)";
CM_ SG_ 382 SAS_SteeringAngleValid "Effective signal for steering angle";
CM_ SG_ 382 SAS_SASStsSnsr "the flag of  SAS status Punch:Steering angle status";
CM_ SG_ 382 SAS_SteerWhlRotSpd "The current rotation speed of the steering wheel.";
CM_ SG_ 382 SAS_SteerWhlRotSpdStatus "The status of SteerWheel Rotation Speed valid";
CM_ SG_ 382 SAS_Calibrated "SAS calibration state of Steer Angle Sensor";
CM_ SG_ 382 SAS_SASFailure "Angle sensor disabled.";
CM_ SG_ 617 Checksum_0x269 "Check sum";
CM_ SG_ 617 RollingCounter_0x269 "Rolling counter";
CM_ SG_ 617 VCU_VehicleHVStatus "Vehicle High voltage Ready State";
CM_ SG_ 617 VCU_ActualGear "actual gear,Provide gear shift signal";
CM_ SG_ 617 VCU_ActualGearValid "Indicate the current gear position Valid";
CM_ SG_ 617 VCU_AccPedalPosition "Indicate the acceleraton pedal position";
CM_ SG_ 617 VCU_AccPedalPositionValid "Indicate the acceleration pedal position valid flag";
CM_ SG_ 617 VCU_TqReductionRqstResponse "Indicate the response for the RBS/TCS request torqueRBS/TCS";
CM_ SG_ 617 VCU_BrakePedalSts "Brake Pedal Sts";
CM_ SG_ 524 Checksum_0x20C "Checksum";
CM_ SG_ 524 Rolling_Counter_0x20C "Rolling_Counter";
CM_ SG_ 524 IPC_ODO "odograph";
CM_ SG_ 703 IPC_TripA "Set Trip A";
CM_ SG_ 703 IPC_AverageSpeedTripA "Average Speed of TripA";
CM_ SG_ 703 IPC_AverageConsumptionTripA "Average Consumption of TripA";
CM_ SG_ 703 IPC_ParkBrakeSts "Park Brake Status";
CM_ SG_ 703 IPC_VehSpd "Current Displayed Longitudinal Vehicle Speed";
CM_ SG_ 735 IPC_TireLearningReq_reserved "IPC request to ready to learning";
CM_ SG_ 735 IPC_TireResetReq "IPC request iTPMS reset";
CM_ SG_ 1087 IPC_Sec "Represents the current second.60 - 63 = Invalid";
CM_ SG_ 1087 IPC_Min "Represents the current minute. 60 - 63 = Invalid";
CM_ SG_ 1087 IPC_Hour "Represents the current hour, 24 - 30 = not used";
CM_ SG_ 1087 IPC_Day "Represents the current dayInvalid value = 0";
CM_ SG_ 1087 IPC_Month "Represents the current month.0, 13 to 15 = Invalid";
CM_ SG_ 1087 IPC_Year "Represents the current year.";
CM_ SG_ 1087 IPC_SelfCheckStatus "Power on self check status";
CM_ SG_ 1027 Checksum_0x403 "Checksum";
CM_ SG_ 1027 Rolling_Counter_0x403 "Rolling_Counter";
CM_ SG_ 1027 MHU_SET_TCS_OnOff "Change TCS mode ON/OFF";
CM_ SG_ 1027 MHU_SET_DrivingModeSwitch "Change vehicle driving mode";
CM_ SG_ 1027 MHU_SET_RegenLevel "Set power regenerative level";
CM_ SG_ 1027 MHU_VCU_CreepDisable_stt "Request for VCU to disable creep function";
CM_ SG_ 1027 MHU_ChargeSetTargetSOC "Request for VCU to set target HV SOC";
CM_ SG_ 1027 MHU_HVACTurnON "Turning ON HVAC remotely";
CM_ SG_ 1027 MHU_ChargeScheduleSet "Request for VCU to enable/disable Charging Scheduling";
CM_ SG_ 1027 MHU_ChargingRequest "Request for VCU to ON/OFF Charging when schedule is reached";
CM_ SG_ 1027 MHU_ValetMode_Activation "Activate Valet mode from MHU";
CM_ SG_ 1027 MHU_ValetMode_MaxSpeed "Setting of maximum allowable in valet mode";
CM_ SG_ 848 BCM_STAT_DoorAjarDriver "Ajar Door Driver Status";
CM_ SG_ 848 BCM_PosLmpSts "Position light output Status";
CM_ SG_ 266 Checksum_0x10a "Checksum";
CM_ SG_ 266 Rolling_Counter_0x10a "Rolling Counter";
CM_ SG_ 266 BCM_LVTop_up "LV  battery top up requice signal";
CM_ SG_ 266 Ubatt_Reserved "Battery Voltage(UBatt to be received by all modules,Required for DTC snapshots)";
CM_ SG_ 274 Checksum_0x112 "Checksum";
CM_ SG_ 274 Rolling_Counter_0x112 "Rolling_Counter";
CM_ SG_ 274 STAT_Terminal "Represent the status of physical terminal(STAT_Terminal to be received by all modules,Required for DTC snapshots and for FOTA)";
CM_ SG_ 274 STAT_CL30s_L_Reserved "Status Clamp 30s Logical ON/OFF";
CM_ SG_ 504 Checksum_0x1F8 "Check sum";
CM_ SG_ 504 Rolling_Counter_0x1F8 "Rolling counter";
CM_ SG_ 504 EDS_output_trq_FR "Actual output torque of current EDS";
CM_ SG_ 504 EDS_output_trqValid_FR "Indicate the valid flag of current motor torque";
CM_ SG_ 504 EDS_Spd_FR "current motor speed";
CM_ SG_ 504 EDS_SpdValid_FR "Indicate the valid flag of current motor speed";
CM_ SG_ 504 EDS_MotorDriveSts_FR "The drive state of EDS";
CM_ SG_ 504 EDS_Work_STS_FR "EDS Work status";
CM_ SG_ 504 EDS_powoff_req_FR "If there is a serious failure in the running process of EDS, the high voltage of VCU will be requested";
CM_ SG_ 889 VCU_DriveCoolWaterPumpSts "Motor electronic pump state";
CM_ SG_ 889 VCU_DriveCoolWaterDuty "Motor electronic pump occupancy";
CM_ SG_ 889 VCU_BatteryWaterPumpSts_reserved "Battery electronic pump state";
CM_ SG_ 889 VCU_BatteryWaterPumpDuty_reserved "Battery electronic pump occupancy";
CM_ SG_ 889 VCU_DriveMode "Vehicle drive mode";
CM_ SG_ 889 VCU_ActualGear "actual gear,Provide gear shift signal";
CM_ SG_ 889 VCU_ACTGearValid "Indicate the current gear position";
CM_ SG_ 889 VCU_AccPedal1OutRange "The state of accelerator pedal1";
CM_ SG_ 889 VCU_AccPedal2OutRange "The state of accelerator pedal2";
CM_ SG_ 889 VCU_BrkPedal1OutRange "The synchronization state of brake pedal1";
CM_ SG_ 889 VCU_BrkPedal2OutRange "The state of barke pedal2";
CM_ SG_ 889 VCU_BrkPedalPct "The percent of brake pedal";
CM_ SG_ 889 VCU_AccPedalPosition "Indicate the acceleraton pedal position";
CM_ SG_ 889 VCU_AccPedalPositionValid "Indicate the acceleration pedal position valid flag";
CM_ SG_ 889 VCU_SocDisplay_EST "Battery SOC";
CM_ SG_ 889 VCU_PowerLimit "Vehicle power limit";
CM_ SG_ 889 VCU_CruiseCtrlSts "Cruise state";
CM_ SG_ 889 VCU_LowSOC_ERR "Battery SOC low";
CM_ SG_ 1705 ESC_DiagReqData0 "Data0";
CM_ SG_ 1705 ESC_DiagReqData1 "Data1";
CM_ SG_ 1705 ESC_DiagReqData2 "Data2";
CM_ SG_ 1705 ESC_DiagReqData3 "Data3";
CM_ SG_ 1705 ESC_DiagReqData4 "Data4";
CM_ SG_ 1705 ESC_DiagReqData5 "Data5";
CM_ SG_ 1705 ESC_DiagReqData6 "Data6";
CM_ SG_ 1705 ESC_DiagReqData7 "Data7";
CM_ SG_ 1577 ESC_DiagRespData0 "Data0";
CM_ SG_ 1577 ESC_DiagRespData1 "Data1";
CM_ SG_ 1577 ESC_DiagRespData2 "Data2";
CM_ SG_ 1577 ESC_DiagRespData3 "Data3";
CM_ SG_ 1577 ESC_DiagRespData4 "Data4";
CM_ SG_ 1577 ESC_DiagRespData5 "Data5";
CM_ SG_ 1577 ESC_DiagRespData6 "Data6";
CM_ SG_ 1577 ESC_DiagRespData7 "Data7";
CM_ SG_ 1791 GW_DiagFunctionalAddressingData0 "Data0";
CM_ SG_ 1791 GW_DiagFunctionalAddressingData1 "Data1";
CM_ SG_ 1791 GW_DiagFunctionalAddressingData2 "Data2";
CM_ SG_ 1791 GW_DiagFunctionalAddressingData3 "Data3";
CM_ SG_ 1791 GW_DiagFunctionalAddressingData4 "Data4";
CM_ SG_ 1791 GW_DiagFunctionalAddressingData5 "Data5";
CM_ SG_ 1791 GW_DiagFunctionalAddressingData6 "Data6";
CM_ SG_ 1791 GW_DiagFunctionalAddressingData7 "Data7";
BA_DEF_ BO_ "DiagRequest" ENUM "No","Yes";
BA_DEF_ BO_ "DiagResponse" ENUM "No","Yes";
BA_DEF_ BO_ "DiagState" ENUM "No","Yes";
BA_DEF_ BO_ "GenMsgCycleTime" INT 0 65535;
BA_DEF_ BO_ "GenMsgCycleTimeFast" INT 0 65535;
BA_DEF_ BO_ "GenMsgDelayTime" INT 0 65535;
BA_DEF_ BO_ "GenMsgILSupport" ENUM "No","Yes";
BA_DEF_ BO_ "GenMsgNrOfRepetition" INT 0 65535;
BA_DEF_ BO_ "GenMsgSendType" ENUM  "Cycle","Event","IfActive","CE","CA";
BA_DEF_ SG_ "GenSigSendType" ENUM  "Cycle","OnWrite","OnWriteWithRepetition","OnChange","OnChangeWithRepetition","IfActive","IfActiveWithRepetition";
BA_DEF_ SG_ "GenSigStartValue" INT 0 2147483647;
BA_DEF_ SG_ "GenSigInvalidValue" INT 0 2147483647;
BA_DEF_ SG_ "GenSigInactiveValue" INT 0 2147483647;
BA_DEF_ BU_ "ILUsed" ENUM  "No","Yes";
BA_DEF_ BU_ "NmAsrCanMsgReducedTime" INT 320 640;
BA_DEF_  "Baudrate" INT 0 1000000;
BA_DEF_  "BusType" STRING;
BA_DEF_  "Manufacturer" STRING;
BA_DEF_  "NmAsrBaseAddress" HEX 0 2047;
BA_DEF_  "NmAsrCanMsgCycleTime" INT 0 65535;
BA_DEF_  "NmAsrMessageCount" INT 1 256;
BA_DEF_  "NmAsrRepeatMessageTime" INT 0 65535;
BA_DEF_  "NmAsrTimeoutTime" INT 0 65535;
BA_DEF_  "NmAsrWaitBusSleepTime" INT 0 65535;
BA_DEF_  "NmType" STRING;
BA_DEF_DEF_ "Baudrate" 500000;
BA_DEF_DEF_ "BusType" "CAN";
BA_DEF_DEF_ "DiagRequest" "No";
BA_DEF_DEF_ "DiagResponse" "No";
BA_DEF_DEF_ "DiagState" "No";
BA_DEF_DEF_ "GenMsgCycleTime" 0;
BA_DEF_DEF_ "GenMsgCycleTimeFast" 0;
BA_DEF_DEF_ "GenMsgDelayTime" 0;
BA_DEF_DEF_ "GenMsgILSupport" "Yes";
BA_DEF_DEF_ "GenMsgNrOfRepetition" 0;
BA_DEF_DEF_ "GenMsgSendType" "NoMsgSendType";
BA_DEF_DEF_ "GenSigSendType" "NoSigSendType";
BA_DEF_DEF_ "GenSigStartValue" 0;
BA_DEF_DEF_  "GenSigInvalidValue" 0;
BA_DEF_DEF_ "GenSigInactiveValue" 0;
BA_DEF_DEF_ "ILUsed" "Yes";
BA_DEF_DEF_ "Manufacturer" "Launch";
BA_DEF_DEF_ "NmAsrBaseAddress" 1280;
BA_DEF_DEF_ "NmAsrCanMsgCycleTime" 640;
BA_DEF_DEF_ "NmAsrCanMsgReducedTime" 320;
BA_DEF_DEF_ "NmAsrMessageCount" 128;
BA_DEF_DEF_ "NmAsrRepeatMessageTime" 3200;
BA_DEF_DEF_ "NmAsrTimeoutTime" 2000;
BA_DEF_DEF_ "NmAsrWaitBusSleepTime" 1500;
BA_DEF_DEF_ "NmType" "NmAsr";

BA_ "GenMsgSendType" BO_ 306 0;
BA_ "GenMsgCycleTime" BO_ 306 20;
BA_ "GenMsgSendType" BO_ 322 0;
BA_ "GenMsgCycleTime" BO_ 322 20;
BA_ "GenMsgSendType" BO_ 818 0;
BA_ "GenMsgCycleTime" BO_ 818 10;
BA_ "GenMsgSendType" BO_ 834 0;
BA_ "GenMsgCycleTime" BO_ 834 10;
BA_ "GenMsgSendType" BO_ 610 0;
BA_ "GenMsgCycleTime" BO_ 610 10;
BA_ "GenMsgSendType" BO_ 994 0;
BA_ "GenMsgCycleTime" BO_ 994 20;
BA_ "GenMsgSendType" BO_ 1010 0;
BA_ "GenMsgCycleTime" BO_ 1010 20;
BA_ "GenMsgSendType" BO_ 866 0;
BA_ "GenMsgCycleTime" BO_ 866 20;
BA_ "GenMsgSendType" BO_ 1154 0;
BA_ "GenMsgCycleTime" BO_ 1154 50;
BA_ "GenMsgSendType" BO_ 382 0;
BA_ "GenMsgCycleTime" BO_ 382 10;
BA_ "GenMsgSendType" BO_ 617 0;
BA_ "GenMsgCycleTime" BO_ 617 20;
BA_ "GenMsgSendType" BO_ 524 0;
BA_ "GenMsgCycleTime" BO_ 524 100;
BA_ "GenMsgSendType" BO_ 703 0;
BA_ "GenMsgCycleTime" BO_ 703 50;
BA_ "GenMsgSendType" BO_ 735 1;
BA_ "GenMsgNrOfRepetition" BO_ 735 5;
BA_ "GenMsgCycleTimeFast" BO_ 735 50;
BA_ "GenMsgSendType" BO_ 1087 0;
BA_ "GenMsgCycleTime" BO_ 1087 1000;
BA_ "GenMsgSendType" BO_ 1027 3;
BA_ "GenMsgNrOfRepetition" BO_ 1027 5;
BA_ "GenMsgCycleTimeFast" BO_ 1027 20;
BA_ "GenMsgCycleTime" BO_ 1027 100;
BA_ "GenMsgSendType" BO_ 848 0;
BA_ "GenMsgCycleTime" BO_ 848 50;
BA_ "GenMsgSendType" BO_ 266 0;
BA_ "GenMsgCycleTime" BO_ 266 100;
BA_ "GenMsgSendType" BO_ 274 0;
BA_ "GenMsgCycleTime" BO_ 274 100;
BA_ "GenMsgSendType" BO_ 504 0;
BA_ "GenMsgCycleTime" BO_ 504 10;
BA_ "GenMsgSendType" BO_ 889 0;
BA_ "GenMsgCycleTime" BO_ 889 50;
BA_ "GenMsgSendType" BO_ 1705 1;
BA_ "DiagRequest" BO_ 1705 1;
BA_ "GenMsgSendType" BO_ 1577 1;
BA_ "DiagResponse" BO_ 1577 1;
BA_ "GenMsgSendType" BO_ 1791 1;
BA_ "DiagState" BO_ 1791 1;
BA_ "GenSigSendType" SG_ 306 Checksum_0x132 0;
BA_ "GenSigSendType" SG_ 306 RollingCounter_0x132 0;
BA_ "GenSigInvalidValue" SG_ 306 RollingCounter_0x132 15;
BA_ "GenSigSendType" SG_ 306 ESC_HSA_Control_Status 0;
BA_ "GenSigSendType" SG_ 306 ESC_HSA_Status_Fault 0;
BA_ "GenSigSendType" SG_ 306 ESC_TcsDisableSts 0;
BA_ "GenSigInvalidValue" SG_ 306 ESC_TcsDisableSts 3;
BA_ "GenSigSendType" SG_ 306 ESC_TcsCtrlActv 0;
BA_ "GenSigSendType" SG_ 306 ESC_TcsFlgFlt 0;
BA_ "GenSigSendType" SG_ 306 ESC_EscDisableSts 0;
BA_ "GenSigSendType" SG_ 306 ESC_EscCtrlActv 0;
BA_ "GenSigSendType" SG_ 306 ESC_EscFlgFlt 0;
BA_ "GenSigSendType" SG_ 306 ESC_HBAFlgFlt 0;
BA_ "GenSigSendType" SG_ 306 ESC_HbaCtrlActv 0;
BA_ "GenSigSendType" SG_ 306 ESC_SlopeGradeAngle 0;
BA_ "GenSigInvalidValue" SG_ 306 ESC_SlopeGradeAngle 255;
BA_ "GenSigSendType" SG_ 306 ESC_MasterCylinderPressure 0;
BA_ "GenSigInvalidValue" SG_ 306 ESC_MasterCylinderPressure 4095;
BA_ "GenSigStartValue" SG_ 306 ESC_MasterCylinderPressure 1000;
BA_ "GenSigSendType" SG_ 322 Checksum_0x142 0;
BA_ "GenSigSendType" SG_ 322 RollingCounter_0x142 0;
BA_ "GenSigInvalidValue" SG_ 322 RollingCounter_0x142 15;
BA_ "GenSigSendType" SG_ 322 AbsDiagSessionLampReq_Reserved 0;
BA_ "GenSigSendType" SG_ 322 ABS_AbsCtrlActv 0;
BA_ "GenSigSendType" SG_ 322 ABS_EbdFlgFlt 0;
BA_ "GenSigSendType" SG_ 322 ABS_AbsFlgFlt 0;
BA_ "GenSigSendType" SG_ 322 ABS_ESS_Active 0;
BA_ "GenSigSendType" SG_ 322 ABS_LowBrakeFluid 0;
BA_ "GenSigSendType" SG_ 818 Checksum_0x332 0;
BA_ "GenSigSendType" SG_ 818 RollingCounter_0x332 0;
BA_ "GenSigInvalidValue" SG_ 818 RollingCounter_0x332 15;
BA_ "GenSigSendType" SG_ 818 ABS_LFWhlSpdRaw 0;
BA_ "GenSigInvalidValue" SG_ 818 ABS_LFWhlSpdRaw 32767;
BA_ "GenSigSendType" SG_ 818 ABS_LFWhlSpdRawValid 0;
BA_ "GenSigSendType" SG_ 818 ABS_RFWhlSpdRaw 0;
BA_ "GenSigInvalidValue" SG_ 818 ABS_RFWhlSpdRaw 32767;
BA_ "GenSigSendType" SG_ 818 ABS_RFWhlSpdRawValid 0;
BA_ "GenSigSendType" SG_ 834 Checksum_0x342 0;
BA_ "GenSigSendType" SG_ 834 RollingCounter_0x342 0;
BA_ "GenSigInvalidValue" SG_ 834 RollingCounter_0x342 15;
BA_ "GenSigSendType" SG_ 834 ABS_LRWhlSpdRaw 0;
BA_ "GenSigInvalidValue" SG_ 834 ABS_LRWhlSpdRaw 32767;
BA_ "GenSigSendType" SG_ 834 ABS_LRWhlSpdRawValid 0;
BA_ "GenSigSendType" SG_ 834 ABS_RRWhlSpdRaw 0;
BA_ "GenSigInvalidValue" SG_ 834 ABS_RRWhlSpdRaw 32767;
BA_ "GenSigSendType" SG_ 834 ABS_RRWhlSpdRawValid 0;
BA_ "GenSigSendType" SG_ 834 ABS_VehSpd 0;
BA_ "GenSigInvalidValue" SG_ 834 ABS_VehSpd 32767;
BA_ "GenSigSendType" SG_ 834 ABS_VehSpdValid 0;
BA_ "GenSigSendType" SG_ 610 ABS_WssLFPulseCounter 0;
BA_ "GenSigInvalidValue" SG_ 610 ABS_WssLFPulseCounter 32767;
BA_ "GenSigSendType" SG_ 610 ABS_WssLFPulseCounterValid 0;
BA_ "GenSigSendType" SG_ 610 ABS_WssRFPulseCounter 0;
BA_ "GenSigInvalidValue" SG_ 610 ABS_WssRFPulseCounter 32767;
BA_ "GenSigSendType" SG_ 610 ABS_WssRFPulseCounterValid 0;
BA_ "GenSigSendType" SG_ 610 ABS_WssLRPulseCounter 0;
BA_ "GenSigInvalidValue" SG_ 610 ABS_WssLRPulseCounter 32767;
BA_ "GenSigSendType" SG_ 610 ABS_WssLRPulseCounterValid 0;
BA_ "GenSigSendType" SG_ 610 ABS_WssRRPulseCounter 0;
BA_ "GenSigInvalidValue" SG_ 610 ABS_WssRRPulseCounter 32767;
BA_ "GenSigSendType" SG_ 610 ABS_WssRRPulseCounterValid 0;
BA_ "GenSigSendType" SG_ 994 Checksum_0x3E2 0;
BA_ "GenSigSendType" SG_ 994 RollingCounter_0x3E2 0;
BA_ "GenSigInvalidValue" SG_ 994 RollingCounter_0x3E2 15;
BA_ "GenSigSendType" SG_ 994 ESC_LateralACC 0;
BA_ "GenSigInvalidValue" SG_ 994 ESC_LateralACC 255;
BA_ "GenSigStartValue" SG_ 994 ESC_LateralACC 127;
BA_ "GenSigSendType" SG_ 994 ESC_LateralACC_Valid 0;
BA_ "GenSigSendType" SG_ 994 ESC_LongitudeACC 0;
BA_ "GenSigInvalidValue" SG_ 994 ESC_LongitudeACC 1023;
BA_ "GenSigStartValue" SG_ 994 ESC_LongitudeACC 511;
BA_ "GenSigSendType" SG_ 994 ESC_LongitudeACC_Valid 0;
BA_ "GenSigSendType" SG_ 994 ESC_VehDynYawRate 0;
BA_ "GenSigInvalidValue" SG_ 994 ESC_VehDynYawRate 16383;
BA_ "GenSigSendType" SG_ 994 ESC_VehDynYawRate_Valid 0;
BA_ "GenSigSendType" SG_ 1010 Checksum_0x3F2 0;
BA_ "GenSigSendType" SG_ 1010 RollingCounter_0x3F2 0;
BA_ "GenSigInvalidValue" SG_ 1010 RollingCounter_0x3F2 15;
BA_ "GenSigSendType" SG_ 1010 ESC_VehicleACC 0;
BA_ "GenSigInvalidValue" SG_ 1010 ESC_VehicleACC 1023;
BA_ "GenSigStartValue" SG_ 1010 ESC_VehicleACC 511;
BA_ "GenSigSendType" SG_ 1010 ESC_VehicleACC_Valid 0;
BA_ "GenSigSendType" SG_ 866 Checksum_362 0;
BA_ "GenSigSendType" SG_ 866 RollingCounter_362 0;
BA_ "GenSigInvalidValue" SG_ 866 RollingCounter_362 15;
BA_ "GenSigSendType" SG_ 866 ESC_RegenDragCtrlStatus 0;
BA_ "GenSigSendType" SG_ 866 ESC_RegenBrakeCtrlStatus 0;
BA_ "GenSigSendType" SG_ 866 ESC_TorqReqMode 0;
BA_ "GenSigSendType" SG_ 866 ESC_TorqRequestVal 0;
BA_ "GenSigInvalidValue" SG_ 866 ESC_TorqRequestVal 65535;
BA_ "GenSigSendType" SG_ 1154 ESC_FLTirePressAlarm 0;
BA_ "GenSigInvalidValue" SG_ 1154 ESC_FLTirePressAlarm 1;
BA_ "GenSigSendType" SG_ 1154 ESC_FRTirePressAlarm 0;
BA_ "GenSigInvalidValue" SG_ 1154 ESC_FRTirePressAlarm 1;
BA_ "GenSigSendType" SG_ 1154 ESC_RLTirePressAlarm 0;
BA_ "GenSigInvalidValue" SG_ 1154 ESC_RLTirePressAlarm 1;
BA_ "GenSigSendType" SG_ 1154 ESC_RRTirePressAlarm 0;
BA_ "GenSigInvalidValue" SG_ 1154 ESC_RRTirePressAlarm 1;
BA_ "GenSigSendType" SG_ 1154 ESC_iTPMS_Err 0;
BA_ "GenSigInvalidValue" SG_ 1154 ESC_iTPMS_Err 1;
BA_ "GenSigSendType" SG_ 1154 ESC_iTPMS_WarnLampAct 0;
BA_ "GenSigInvalidValue" SG_ 1154 ESC_iTPMS_WarnLampAct 1;
BA_ "GenSigSendType" SG_ 1154 ESC_iTPMSResetProhibit 0;
BA_ "GenSigSendType" SG_ 1154 ESC_iTPMSResetSts 0;
BA_ "GenSigSendType" SG_ 382 Checksum_0x17E 0;
BA_ "GenSigSendType" SG_ 382 Rolling_counter_0x17E 0;
BA_ "GenSigInvalidValue" SG_ 382 Rolling_counter_0x17E 15;
BA_ "GenSigSendType" SG_ 382 SAS_SteerWheelAngle 0;
BA_ "GenSigInvalidValue" SG_ 382 SAS_SteerWheelAngle 65535;
BA_ "GenSigStartValue" SG_ 382 SAS_SteerWheelAngle 32773;
BA_ "GenSigSendType" SG_ 382 SAS_SteeringAngleValid 0;
BA_ "GenSigSendType" SG_ 382 SAS_SASStsSnsr 0;
BA_ "GenSigSendType" SG_ 382 SAS_SteerWhlRotSpd 0;
BA_ "GenSigInvalidValue" SG_ 382 SAS_SteerWhlRotSpd 16383;
BA_ "GenSigSendType" SG_ 382 SAS_SteerWhlRotSpdStatus 0;
BA_ "GenSigSendType" SG_ 382 SAS_Calibrated 0;
BA_ "GenSigSendType" SG_ 382 SAS_SASFailure 0;
BA_ "GenSigSendType" SG_ 617 Checksum_0x269 0;
BA_ "GenSigSendType" SG_ 617 RollingCounter_0x269 0;
BA_ "GenSigInvalidValue" SG_ 617 RollingCounter_0x269 15;
BA_ "GenSigSendType" SG_ 617 VCU_VehicleHVStatus 0;
BA_ "GenSigInvalidValue" SG_ 617 VCU_VehicleHVStatus 3;
BA_ "GenSigSendType" SG_ 617 VCU_ActualGear 0;
BA_ "GenSigInvalidValue" SG_ 617 VCU_ActualGear 7;
BA_ "GenSigStartValue" SG_ 617 VCU_ActualGear 2;
BA_ "GenSigSendType" SG_ 617 VCU_ActualGearValid 0;
BA_ "GenSigInvalidValue" SG_ 617 VCU_ActualGearValid 1;
BA_ "GenSigSendType" SG_ 617 VCU_AccPedalPosition 0;
BA_ "GenSigInvalidValue" SG_ 617 VCU_AccPedalPosition 255;
BA_ "GenSigSendType" SG_ 617 VCU_AccPedalPositionValid 0;
BA_ "GenSigInvalidValue" SG_ 617 VCU_AccPedalPositionValid 1;
BA_ "GenSigSendType" SG_ 617 VCU_TqReductionRqstResponse 0;
BA_ "GenSigStartValue" SG_ 617 VCU_TqReductionRqstResponse 1;
BA_ "GenSigSendType" SG_ 617 VCU_BrakePedalSts 0;
BA_ "GenSigInvalidValue" SG_ 617 VCU_BrakePedalSts 3;
BA_ "GenSigSendType" SG_ 524 Checksum_0x20C 0;
BA_ "GenSigSendType" SG_ 524 Rolling_Counter_0x20C 0;
BA_ "GenSigInvalidValue" SG_ 524 Rolling_Counter_0x20C 15;
BA_ "GenSigSendType" SG_ 524 IPC_ODO 0;
BA_ "GenSigInvalidValue" SG_ 524 IPC_ODO 1048575;
BA_ "GenSigSendType" SG_ 703 IPC_TripA 0;
BA_ "GenSigInvalidValue" SG_ 703 IPC_TripA 65535;
BA_ "GenSigSendType" SG_ 703 IPC_AverageSpeedTripA 0;
BA_ "GenSigInvalidValue" SG_ 703 IPC_AverageSpeedTripA 4095;
BA_ "GenSigSendType" SG_ 703 IPC_AverageConsumptionTripA 0;
BA_ "GenSigInvalidValue" SG_ 703 IPC_AverageConsumptionTripA 1023;
BA_ "GenSigSendType" SG_ 703 IPC_ParkBrakeSts 0;
BA_ "GenSigInvalidValue" SG_ 703 IPC_ParkBrakeSts 3;
BA_ "GenSigSendType" SG_ 703 IPC_VehSpd 0;
BA_ "GenSigInvalidValue" SG_ 703 IPC_VehSpd 32767;
BA_ "GenSigSendType" SG_ 735 IPC_TireLearningReq_reserved 4;
BA_ "GenSigSendType" SG_ 735 IPC_TireResetReq 4;
BA_ "GenSigSendType" SG_ 1087 IPC_Sec 0;
BA_ "GenSigInvalidValue" SG_ 1087 IPC_Sec 63;
BA_ "GenSigSendType" SG_ 1087 IPC_Min 0;
BA_ "GenSigInvalidValue" SG_ 1087 IPC_Min 63;
BA_ "GenSigSendType" SG_ 1087 IPC_Hour 0;
BA_ "GenSigInvalidValue" SG_ 1087 IPC_Hour 31;
BA_ "GenSigSendType" SG_ 1087 IPC_Day 0;
BA_ "GenSigInvalidValue" SG_ 1087 IPC_Day 31;
BA_ "GenSigStartValue" SG_ 1087 IPC_Day 1;
BA_ "GenSigSendType" SG_ 1087 IPC_Month 0;
BA_ "GenSigInvalidValue" SG_ 1087 IPC_Month 15;
BA_ "GenSigStartValue" SG_ 1087 IPC_Month 1;
BA_ "GenSigSendType" SG_ 1087 IPC_Year 0;
BA_ "GenSigInvalidValue" SG_ 1087 IPC_Year 255;
BA_ "GenSigSendType" SG_ 1087 IPC_SelfCheckStatus 0;
BA_ "GenSigSendType" SG_ 1027 Checksum_0x403 0;
BA_ "GenSigSendType" SG_ 1027 Rolling_Counter_0x403 0;
BA_ "GenSigInvalidValue" SG_ 1027 Rolling_Counter_0x403 15;
BA_ "GenSigSendType" SG_ 1027 MHU_SET_TCS_OnOff 2;
BA_ "GenSigInvalidValue" SG_ 1027 MHU_SET_TCS_OnOff 3;
BA_ "GenSigStartValue" SG_ 1027 MHU_SET_TCS_OnOff 2;
BA_ "GenSigSendType" SG_ 1027 MHU_SET_DrivingModeSwitch 2;
BA_ "GenSigSendType" SG_ 1027 MHU_SET_RegenLevel 2;
BA_ "GenSigStartValue" SG_ 1027 MHU_SET_RegenLevel 3;
BA_ "GenSigSendType" SG_ 1027 MHU_VCU_CreepDisable_stt 2;
BA_ "GenSigInvalidValue" SG_ 1027 MHU_VCU_CreepDisable_stt 3;
BA_ "GenSigSendType" SG_ 1027 MHU_ChargeSetTargetSOC 2;
BA_ "GenSigInvalidValue" SG_ 1027 MHU_ChargeSetTargetSOC 127;
BA_ "GenSigStartValue" SG_ 1027 MHU_ChargeSetTargetSOC 100;
BA_ "GenSigSendType" SG_ 1027 MHU_HVACTurnON 2;
BA_ "GenSigInvalidValue" SG_ 1027 MHU_HVACTurnON 3;
BA_ "GenSigSendType" SG_ 1027 MHU_ChargeScheduleSet 2;
BA_ "GenSigStartValue" SG_ 1027 MHU_ChargeScheduleSet 2;
BA_ "GenSigSendType" SG_ 1027 MHU_ChargingRequest 2;
BA_ "GenSigStartValue" SG_ 1027 MHU_ChargingRequest 3;
BA_ "GenSigSendType" SG_ 1027 MHU_ValetMode_Activation 2;
BA_ "GenSigInvalidValue" SG_ 1027 MHU_ValetMode_Activation 254;
BA_ "GenSigInactiveValue" SG_ 1027 MHU_ValetMode_Activation 255;
BA_ "GenSigSendType" SG_ 1027 MHU_ValetMode_MaxSpeed 2;
BA_ "GenSigInvalidValue" SG_ 1027 MHU_ValetMode_MaxSpeed 2;
BA_ "GenSigInactiveValue" SG_ 1027 MHU_ValetMode_MaxSpeed 255;
BA_ "GenSigSendType" SG_ 848 BCM_STAT_DoorAjarDriver 0;
BA_ "GenSigSendType" SG_ 848 BCM_PosLmpSts 0;
BA_ "GenSigSendType" SG_ 266 Checksum_0x10a 0;
BA_ "GenSigSendType" SG_ 266 Rolling_Counter_0x10a 0;
BA_ "GenSigInvalidValue" SG_ 266 Rolling_Counter_0x10a 15;
BA_ "GenSigSendType" SG_ 266 BCM_LVTop_up 0;
BA_ "GenSigSendType" SG_ 266 Ubatt_Reserved 0;
BA_ "GenSigInvalidValue" SG_ 266 Ubatt_Reserved 16383;
BA_ "GenSigStartValue" SG_ 266 Ubatt_Reserved 9000;
BA_ "GenSigSendType" SG_ 274 Checksum_0x112 0;
BA_ "GenSigSendType" SG_ 274 Rolling_Counter_0x112 0;
BA_ "GenSigInvalidValue" SG_ 274 Rolling_Counter_0x112 15;
BA_ "GenSigSendType" SG_ 274 STAT_Terminal 0;
BA_ "GenSigSendType" SG_ 274 STAT_CL30s_L_Reserved 0;
BA_ "GenSigStartValue" SG_ 274 STAT_CL30s_L_Reserved 3;
BA_ "GenSigSendType" SG_ 504 Checksum_0x1F8 0;
BA_ "GenSigSendType" SG_ 504 Rolling_Counter_0x1F8 0;
BA_ "GenSigInvalidValue" SG_ 504 Rolling_Counter_0x1F8 15;
BA_ "GenSigSendType" SG_ 504 EDS_output_trq_FR 0;
BA_ "GenSigInvalidValue" SG_ 504 EDS_output_trq_FR 65535;
BA_ "GenSigStartValue" SG_ 504 EDS_output_trq_FR 2000;
BA_ "GenSigSendType" SG_ 504 EDS_output_trqValid_FR 0;
BA_ "GenSigSendType" SG_ 504 EDS_Spd_FR 0;
BA_ "GenSigInvalidValue" SG_ 504 EDS_Spd_FR 65535;
BA_ "GenSigStartValue" SG_ 504 EDS_Spd_FR 20000;
BA_ "GenSigSendType" SG_ 504 EDS_SpdValid_FR 0;
BA_ "GenSigSendType" SG_ 504 EDS_MotorDriveSts_FR 0;
BA_ "GenSigInvalidValue" SG_ 504 EDS_MotorDriveSts_FR 3;
BA_ "GenSigSendType" SG_ 504 EDS_Work_STS_FR 0;
BA_ "GenSigInvalidValue" SG_ 504 EDS_Work_STS_FR 15;
BA_ "GenSigSendType" SG_ 504 EDS_powoff_req_FR 0;
BA_ "GenSigSendType" SG_ 889 VCU_DriveCoolWaterPumpSts 0;
BA_ "GenSigSendType" SG_ 889 VCU_DriveCoolWaterDuty 0;
BA_ "GenSigInvalidValue" SG_ 889 VCU_DriveCoolWaterDuty 127;
BA_ "GenSigSendType" SG_ 889 VCU_BatteryWaterPumpSts_reserved 0;
BA_ "GenSigSendType" SG_ 889 VCU_BatteryWaterPumpDuty_reserved 0;
BA_ "GenSigInvalidValue" SG_ 889 VCU_BatteryWaterPumpDuty_reserved 127;
BA_ "GenSigSendType" SG_ 889 VCU_DriveMode 0;
BA_ "GenSigInvalidValue" SG_ 889 VCU_DriveMode 7;
BA_ "GenSigStartValue" SG_ 889 VCU_DriveMode 1;
BA_ "GenSigSendType" SG_ 889 VCU_ActualGear 0;
BA_ "GenSigInvalidValue" SG_ 889 VCU_ActualGear 7;
BA_ "GenSigStartValue" SG_ 889 VCU_ActualGear 2;
BA_ "GenSigSendType" SG_ 889 VCU_ACTGearValid 0;
BA_ "GenSigInvalidValue" SG_ 889 VCU_ACTGearValid 1;
BA_ "GenSigSendType" SG_ 889 VCU_AccPedal1OutRange 0;
BA_ "GenSigSendType" SG_ 889 VCU_AccPedal2OutRange 0;
BA_ "GenSigSendType" SG_ 889 VCU_BrkPedal1OutRange 0;
BA_ "GenSigSendType" SG_ 889 VCU_BrkPedal2OutRange 0;
BA_ "GenSigSendType" SG_ 889 VCU_BrkPedalPct 0;
BA_ "GenSigInvalidValue" SG_ 889 VCU_BrkPedalPct 255;
BA_ "GenSigSendType" SG_ 889 VCU_AccPedalPosition 0;
BA_ "GenSigInvalidValue" SG_ 889 VCU_AccPedalPosition 255;
BA_ "GenSigSendType" SG_ 889 VCU_AccPedalPositionValid 0;
BA_ "GenSigInvalidValue" SG_ 889 VCU_AccPedalPositionValid 1;
BA_ "GenSigStartValue" SG_ 889 VCU_AccPedalPositionValid 1;
BA_ "GenSigSendType" SG_ 889 VCU_SocDisplay_EST 0;
BA_ "GenSigInvalidValue" SG_ 889 VCU_SocDisplay_EST 127;
BA_ "GenSigSendType" SG_ 889 VCU_PowerLimit 0;
BA_ "GenSigSendType" SG_ 889 VCU_CruiseCtrlSts 0;
BA_ "GenSigSendType" SG_ 889 VCU_LowSOC_ERR 0;
BA_ "GenSigSendType" SG_ 1705 ESC_DiagReqData0 0;
BA_ "GenSigSendType" SG_ 1705 ESC_DiagReqData1 0;
BA_ "GenSigSendType" SG_ 1705 ESC_DiagReqData2 0;
BA_ "GenSigSendType" SG_ 1705 ESC_DiagReqData3 0;
BA_ "GenSigSendType" SG_ 1705 ESC_DiagReqData4 0;
BA_ "GenSigSendType" SG_ 1705 ESC_DiagReqData5 0;
BA_ "GenSigSendType" SG_ 1705 ESC_DiagReqData6 0;
BA_ "GenSigSendType" SG_ 1705 ESC_DiagReqData7 0;
BA_ "GenSigSendType" SG_ 1577 ESC_DiagRespData0 0;
BA_ "GenSigSendType" SG_ 1577 ESC_DiagRespData1 0;
BA_ "GenSigSendType" SG_ 1577 ESC_DiagRespData2 0;
BA_ "GenSigSendType" SG_ 1577 ESC_DiagRespData3 0;
BA_ "GenSigSendType" SG_ 1577 ESC_DiagRespData4 0;
BA_ "GenSigSendType" SG_ 1577 ESC_DiagRespData5 0;
BA_ "GenSigSendType" SG_ 1577 ESC_DiagRespData6 0;
BA_ "GenSigSendType" SG_ 1577 ESC_DiagRespData7 0;
BA_ "GenSigSendType" SG_ 1791 GW_DiagFunctionalAddressingData0 0;
BA_ "GenSigSendType" SG_ 1791 GW_DiagFunctionalAddressingData1 0;
BA_ "GenSigSendType" SG_ 1791 GW_DiagFunctionalAddressingData2 0;
BA_ "GenSigSendType" SG_ 1791 GW_DiagFunctionalAddressingData3 0;
BA_ "GenSigSendType" SG_ 1791 GW_DiagFunctionalAddressingData4 0;
BA_ "GenSigSendType" SG_ 1791 GW_DiagFunctionalAddressingData5 0;
BA_ "GenSigSendType" SG_ 1791 GW_DiagFunctionalAddressingData6 0;
BA_ "GenSigSendType" SG_ 1791 GW_DiagFunctionalAddressingData7 0;
VAL_ 306 RollingCounter_0x132 15 "Invalid";
VAL_ 306 ESC_HSA_Control_Status 1 "active" 0 "inactive";
VAL_ 306 ESC_HSA_Status_Fault 1 " HSA Defective" 0 "HSA Normale";
VAL_ 306 ESC_TcsDisableSts 3 "signal invalid" 2 "reservred" 1 "disabled" 0 "enabled";
VAL_ 306 ESC_TcsCtrlActv 1 "active" 0 "inactive";
VAL_ 306 ESC_TcsFlgFlt 1 "failure" 0 "no failure";
VAL_ 306 ESC_EscDisableSts 1 "disabled" 0 "enabled";
VAL_ 306 ESC_EscCtrlActv 1 "active" 0 "inactive";
VAL_ 306 ESC_EscFlgFlt 1 "failure" 0 "no failure";
VAL_ 306 ESC_HBAFlgFlt 1 "failure" 0 "no failure";
VAL_ 306 ESC_HbaCtrlActv 1 "active" 0 "inactive";
VAL_ 306 ESC_SlopeGradeAngle 255 "Invalid";
VAL_ 306 ESC_MasterCylinderPressure 4095 "Invalid";
VAL_ 322 RollingCounter_0x142 15 "Invalid";
VAL_ 322 AbsDiagSessionLampReq_Reserved 1 "lamp on" 0 "lamp off";
VAL_ 322 ABS_AbsCtrlActv 1 "active" 0 "inactive";
VAL_ 322 ABS_EbdFlgFlt 1 "failure" 0 "no failure";
VAL_ 322 ABS_AbsFlgFlt 1 "failure" 0 "no failure";
VAL_ 322 ABS_ESS_Active 1 "active" 0 "inactive";
VAL_ 322 ABS_LowBrakeFluid 1 "failure" 0 "no failure";
VAL_ 818 RollingCounter_0x332 15 "Invalid";
VAL_ 818 ABS_LFWhlSpdRaw 32767 "Invalid";
VAL_ 818 ABS_LFWhlSpdRawValid 1 "Valid" 0 "Invalid";
VAL_ 818 ABS_RFWhlSpdRaw 32767 "Invalid";
VAL_ 818 ABS_RFWhlSpdRawValid 1 "Valid" 0 "Invalid";
VAL_ 834 RollingCounter_0x342 15 "Invalid";
VAL_ 834 ABS_LRWhlSpdRaw 32767 "Invalid";
VAL_ 834 ABS_LRWhlSpdRawValid 1 "Valid" 0 "Invalid";
VAL_ 834 ABS_RRWhlSpdRaw 32767 "Invalid";
VAL_ 834 ABS_RRWhlSpdRawValid 1 "Valid" 0 "Invalid";
VAL_ 834 ABS_VehSpd 32767 "Invalid";
VAL_ 834 ABS_VehSpdValid 1 "Valid" 0 "Invalid";
VAL_ 610 ABS_WssLFPulseCounter 32767 "Invalid";
VAL_ 610 ABS_WssLFPulseCounterValid 1 "Valid" 0 "Invalid";
VAL_ 610 ABS_WssRFPulseCounter 32767 "Invalid";
VAL_ 610 ABS_WssRFPulseCounterValid 1 "Valid" 0 "Invalid";
VAL_ 610 ABS_WssLRPulseCounter 32767 "Invalid";
VAL_ 610 ABS_WssLRPulseCounterValid 1 "Valid" 0 "Invalid";
VAL_ 610 ABS_WssRRPulseCounter 32767 "Invalid";
VAL_ 610 ABS_WssRRPulseCounterValid 1 "Valid" 0 "Invalid";
VAL_ 994 RollingCounter_0x3E2 15 "Invalid";
VAL_ 994 ESC_LateralACC 255 "Invalid";
VAL_ 994 ESC_LateralACC_Valid 1 "Valid" 0 "Invalid";
VAL_ 994 ESC_LongitudeACC 1023 "Invalid";
VAL_ 994 ESC_LongitudeACC_Valid 1 "Valid" 0 "Invalid";
VAL_ 994 ESC_VehDynYawRate 16383 "Invalid";
VAL_ 994 ESC_VehDynYawRate_Valid 1 "Valid" 0 "Invalid";
VAL_ 1010 RollingCounter_0x3F2 15 "Invalid";
VAL_ 1010 ESC_VehicleACC 1023 "Invalid";
VAL_ 1010 ESC_VehicleACC_Valid 1 "Valid" 0 "Invalid";
VAL_ 866 RollingCounter_362 15 "Invalid";
VAL_ 866 ESC_RegenDragCtrlStatus 1 "active" 0 "inactive";
VAL_ 866 ESC_RegenBrakeCtrlStatus 1 "active" 0 "inactive";
VAL_ 866 ESC_TorqReqMode 3 "Reserved" 2 "Regen mode" 1 "TCS mode" 0 "Normal mode";
VAL_ 866 ESC_TorqRequestVal 65535 "Invalid";
VAL_ 1154 ESC_FLTirePressAlarm 1 "Pressure warning" 0 "No warning";
VAL_ 1154 ESC_FRTirePressAlarm 1 "Pressure warning" 0 "No warning";
VAL_ 1154 ESC_RLTirePressAlarm 1 "Pressure warning" 0 "No warning";
VAL_ 1154 ESC_RRTirePressAlarm 1 "Pressure warning" 0 "No warning";
VAL_ 1154 ESC_iTPMS_Err 1 "Error" 0 "No error";
VAL_ 1154 ESC_iTPMS_WarnLampAct 1 "Active" 0 "Inactive";
VAL_ 1154 ESC_iTPMSResetProhibit 3 "prohibit 3 (System error)" 2 "prohibit 2 (Vehicle speed >0 km/h)" 1 "prohibit 1 (Tire statue is changing)" 0 "Not prohibit";
VAL_ 1154 ESC_iTPMSResetSts 4 "Reset fail" 3 "Reset finish" 2 "Reset ongoing" 1 "Reset start" 0 "Idle";
VAL_ 382 Rolling_counter_0x17E 15 "Invalid";
VAL_ 382 SAS_SteerWheelAngle 65535 "Invalid";
VAL_ 382 SAS_SteeringAngleValid 1 "Valid" 0 "Invalid";
VAL_ 382 SAS_SASStsSnsr 1 "sensor value valid" 0 "sensor value Invalid";
VAL_ 382 SAS_SteerWhlRotSpd 16383 "Invalid";
VAL_ 382 SAS_SteerWhlRotSpdStatus 1 "Valid" 0 "Invalid";
VAL_ 382 SAS_Calibrated 1 "Calibrated" 0 "Not Calibrated";
VAL_ 382 SAS_SASFailure 1 "No Failure" 0 "Failure";
VAL_ 617 RollingCounter_0x269 15 "Invalid";
VAL_ 617 VCU_VehicleHVStatus 3 "Reserved" 2 "ReadyToDrive" 1 "HV On" 0 "Not ready";
VAL_ 617 VCU_ActualGear 7 "Fault" 6 "Reserved" 5 "Reserved" 4 "Reserved" 3 "D" 2 "N" 1 "R" 0 "P reserved";
VAL_ 617 VCU_ActualGearValid 1 "Invalid" 0 "Valid";
VAL_ 617 VCU_AccPedalPosition 255 "Invalid";
VAL_ 617 VCU_AccPedalPositionValid 1 "Invalid" 0 "Valid";
VAL_ 617 VCU_TqReductionRqstResponse 1 "active" 0 "inactive";
VAL_ 617 VCU_BrakePedalSts 3 "Invalid" 2 "Reserved" 1 "pressed" 0 "Not pressed";
VAL_ 524 Rolling_Counter_0x20C 15 "Invalid";
VAL_ 524 IPC_ODO 1048575 "Invalid";
VAL_ 703 IPC_TripA 65535 "Invalid";
VAL_ 703 IPC_AverageSpeedTripA 4095 "Invalid";
VAL_ 703 IPC_AverageConsumptionTripA 1023 "Invalid";
VAL_ 703 IPC_ParkBrakeSts 3 "Invalid" 2 "Reserved" 1 "Applied" 0 "Released";
VAL_ 703 IPC_VehSpd 32767 "Invalid";
VAL_ 735 IPC_TireLearningReq_reserved 3 "Reserved" 2 "Reserved" 1 "Requset" 0 "No requset";
VAL_ 735 IPC_TireResetReq 3 "Reserved" 2 "Reserved" 1 "Requset to reset" 0 "No requset";
VAL_ 1087 IPC_Sec 63 "Invalid";
VAL_ 1087 IPC_Min 63 "Invalid";
VAL_ 1087 IPC_Hour 31 "Invalid";
VAL_ 1087 IPC_Day 31 "Invalid";
VAL_ 1087 IPC_Month 15 "Invalid";
VAL_ 1087 IPC_Year 255 "Invalid";
VAL_ 1087 IPC_SelfCheckStatus 1 "self-check finish" 0 "self-checking";
VAL_ 1027 Rolling_Counter_0x403 15 "Invalid";
VAL_ 1027 MHU_SET_TCS_OnOff 0 "OFF (keep sending for 2 seconds)" 1 "ON (keep sending for 2 seconds)" 2 "No action" 3 "Invalid";
VAL_ 1027 MHU_SET_DrivingModeSwitch 3 "sport mode (should be hold during 1 second)" 2 "normal mode (should be hold during 1 second)" 1 "eco mode (should be hold during 1 second)" 0 "no change request";
VAL_ 1027 MHU_SET_RegenLevel 3 "No action" 2 "High" 1 "Low" 0 "none";
VAL_ 1027 MHU_VCU_CreepDisable_stt 0 "No request" 1 "Creep Disable request" 2 "Reserved" 3 "Invalid";
VAL_ 1027 MHU_HVACTurnON 0 "No request" 1 "ON" 2 "Reserved" 3 "Invalid";
VAL_ 1027 MHU_ChargeScheduleSet 0 "Disabled" 1 "Enabled" 2 "No Action" 3 "Reserved";
VAL_ 1027 MHU_ChargingRequest 0 "Reserved" 1 "Request scheduled start charging" 2 "Request stop" 3 "No effect";
VAL_ 1027 MHU_ValetMode_Activation 0 "Inactive" 1 "Active" 254 "Reserved" 255 "Invalid";
VAL_ 848 BCM_STAT_DoorAjarDriver 3 "Signal invalid" 2 "Reserved" 1 "Opened" 0 "Closed";
VAL_ 848 BCM_PosLmpSts 0 "OFF" 1 "ON" 2 "Fault (Reserved)" 3 "Signal Invalid";
VAL_ 266 Rolling_Counter_0x10a 15 "Invalid";
VAL_ 266 BCM_LVTop_up 1 "start Top up" 0 "stop Top up";
VAL_ 274 Rolling_Counter_0x112 15 "Invalid";
VAL_ 274 STAT_Terminal 7 "Signal invalid" 6 "Reserved" 5 "Reserved" 4 "SW update OTA (Not used in VFe34)" 3 "Engine start (eMotor running)" 2 "ON (Driver Present)" 1 "ACC (Park)" 0 "OFF(Comfort Enable)";
VAL_ 274 STAT_CL30s_L_Reserved 3 "Signal invalid" 2 "Failure" 1 "ON" 0 "OFF";
VAL_ 504 Rolling_Counter_0x1F8 15 "Invalid";
VAL_ 504 EDS_output_trq_FR 65535 "Invalid";
VAL_ 504 EDS_output_trqValid_FR 1 "valid" 0 "invalid";
VAL_ 504 EDS_Spd_FR 65535 "Invalid";
VAL_ 504 EDS_SpdValid_FR 1 "valid" 0 "invalid";
VAL_ 504 EDS_MotorDriveSts_FR 3 "Invaild" 2 "regen control" 1 "Drive control" 0 "Zero control";
VAL_ 504 EDS_Work_STS_FR 15 "invaild" 14 "power off" 13 "Failure" 12 "after run" 11 "shut down" 5 "HVReady" 4 "normal" 3 "precharge" 2 "standby" 1 "init" 0 "default";
VAL_ 504 EDS_powoff_req_FR 1 "(Request high voltage power down)" 0 "(No request)";
VAL_ 889 VCU_DriveCoolWaterPumpSts 5 "Reserved" 4 "Other error" 3 "Overtemperature" 2 "Locked-rotor" 1 "Idle" 0 "Normal";
VAL_ 889 VCU_DriveCoolWaterDuty 127 "Invalid";
VAL_ 889 VCU_BatteryWaterPumpSts_reserved 5 "Reserved" 4 "Other error" 3 "Overtemperature" 2 "Locked-rotor" 1 "Idle" 0 "Normal";
VAL_ 889 VCU_BatteryWaterPumpDuty_reserved 127 "Invalid";
VAL_ 889 VCU_DriveMode 7 "Invalid" 6 "Reserved" 5 "Reserved" 4 "Reserved" 3 "Reserved" 2 "Sport mode" 1 "ECO mode" 0 "Normal mode";
VAL_ 889 VCU_ActualGear 7 "Fault" 6 "Reserved" 5 "Reserved" 4 "Reserved" 3 "D" 2 "N" 1 "R" 0 "P reserved";
VAL_ 889 VCU_ACTGearValid 1 "nvalid" 0 "Valid";
VAL_ 889 VCU_AccPedal1OutRange 1 "Error" 0 "Normal";
VAL_ 889 VCU_AccPedal2OutRange 1 "Error" 0 "Normal";
VAL_ 889 VCU_BrkPedal1OutRange 1 "Error" 0 "Normal";
VAL_ 889 VCU_BrkPedal2OutRange 1 "Error" 0 "Normal";
VAL_ 889 VCU_BrkPedalPct 255 "Invalid";
VAL_ 889 VCU_AccPedalPosition 255 "Invalid";
VAL_ 889 VCU_AccPedalPositionValid 1 "Invalid" 0 "Valid";
VAL_ 889 VCU_SocDisplay_EST 127 "Invalid";
VAL_ 889 VCU_PowerLimit 1 "Limit" 0 "No Limit";
VAL_ 889 VCU_CruiseCtrlSts 3 "takeover mode" 2 "Pre cruise(lamp flash)" 1 "Cruise on(lamp on)" 0 "Cruise off(lamp off)";
VAL_ 889 VCU_LowSOC_ERR 1 "Error" 0 "No Error";
